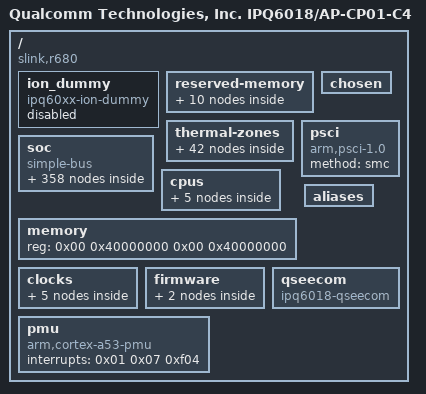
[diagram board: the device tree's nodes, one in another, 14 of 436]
/dts-v1/;

/ {
	qcom,board-id = <0x08 0x00>;
	qcom,pmic-id = <0x00 0x00 0x00 0x00>;
	rpm_version = [43 52 4d 2d 52 50 4d 2e 42 46 2e 32 2e 34 2e 31 2d 30 30 30 39 35 0a];
	tz_version = [43 52 4d 2d 54 5a 2e 57 4e 53 2e 35 2e 31 2d 30 30 31 33 32 0a];
	soc_version_major = <0x1000000>;
	machid = <0x3000308>;
	#size-cells = <0x02>;
	cpu_type = <0xa5010000>;
	interrupt-parent = <0x01>;
	compatible = "slink,r680\0qcom,ipq6018";
	#address-cells = <0x02>;
	model = "Qualcomm Technologies, Inc. IPQ6018/AP-CP01-C4";
	flash_type = <0x5000000>;
	qcom,msm-id = <0x192 0x00 0x193 0x00>;
	soc_version_minor = <0x00>;
	boot_version = [63 72 6d 2d 75 62 75 6e 74 75 31 32 34 2d 42 4f 4f 54 2e 58 46 2e 30 2e 33 2d 30 30 31 30 30 2d 49 50 51 36 30 78 78 4c 5a 42 2d 31 0a];

	ion_dummy {
		compatible = "ipq60xx-ion-dummy";
		status = "disabled";
	};

	reserved-memory {
		ranges;
		#size-cells = <0x02>;
		#address-cells = <0x02>;

		nss@40000000 {
			reg = <0x00 0x40000000 0x00 0x1000000>;
			no-map;
		};

		sbl@4A500000 {
			reg = <0x00 0x4a500000 0x00 0x100000>;
			no-map;
		};

		tzapp@49B00000 {
			reg = <0x00 0x49b00000 0x00 0x600000>;
			no-map;
		};

		rpm_msg_ram@0x60000 {
			linux,phandle = <0x13>;
			reg = <0x00 0x60000 0x00 0x6000>;
			phandle = <0x13>;
			no-map;
		};

		m3_dump@50100000 {
			reg = <0x00 0x50100000 0x00 0x100000>;
			no-map;
		};

		q6_etr_dump@1 {
			linux,phandle = <0x18>;
			reg = <0x00 0x50000000 0x00 0x100000>;
			phandle = <0x18>;
			no-map;
		};

		wcnss@4ab00000 {
			linux,phandle = <0x17>;
			reg = <0x00 0x4ab00000 0x00 0x5500000>;
			phandle = <0x17>;
			no-map;
		};

		tz@4A600000 {
			reg = <0x00 0x4a600000 0x00 0x400000>;
			no-map;
		};

		smem@4AA00000 {
			linux,phandle = <0x11>;
			reg = <0x00 0x4aa00000 0x00 0x100000>;
			phandle = <0x11>;
			no-map;
		};

		uboot@4A100000 {
			reg = <0x00 0x4a100000 0x00 0x400000>;
			no-map;
		};
	};

	thermal-zones {

		tsens_tz_sensor7 {
			thermal-sensors = <0x53 0x07>;
			polling-delay = <0x00>;
			polling-delay-passive = <0x00>;

			trips {

				cpu-critical-hi {
					temperature = <0x7d>;
					type = "critical_high";
					hysteresis = <0x02>;
				};

				cpu-config-hi {
					temperature = <0x69>;
					type = "configurable_hi";
					hysteresis = <0x02>;
				};

				cpu-critical-low {
					temperature = <0x00>;
					type = "critical_low";
					hysteresis = <0x02>;
				};

				cpu-config-lo {
					temperature = <0x5f>;
					type = "configurable_lo";
					hysteresis = <0x02>;
				};
			};
		};

		tsens_tz_sensor15 {
			thermal-sensors = <0x53 0x0f>;
			polling-delay = <0x00>;
			polling-delay-passive = <0x00>;

			trips {

				cpu-critical-hi {
					temperature = <0x7d>;
					type = "critical_high";
					hysteresis = <0x02>;
				};

				cpu-config-hi {
					temperature = <0x69>;
					type = "configurable_hi";
					hysteresis = <0x02>;
				};

				cpu-critical-low {
					temperature = <0x00>;
					type = "critical_low";
					hysteresis = <0x02>;
				};

				cpu-config-lo {
					temperature = <0x5f>;
					type = "configurable_lo";
					hysteresis = <0x02>;
				};
			};
		};

		tsens_tz_sensor13 {
			thermal-sensors = <0x53 0x0d>;
			polling-delay = <0x00>;
			polling-delay-passive = <0x00>;

			trips {

				cpu-critical-hi {
					temperature = <0x7d>;
					type = "critical_high";
					hysteresis = <0x02>;
				};

				cpu-config-hi {
					temperature = <0x69>;
					type = "configurable_hi";
					hysteresis = <0x02>;
				};

				cpu-critical-low {
					temperature = <0x00>;
					type = "critical_low";
					hysteresis = <0x02>;
				};

				cpu-config-lo {
					temperature = <0x5f>;
					type = "configurable_lo";
					hysteresis = <0x02>;
				};
			};
		};

		tsens_tz_sensor8 {
			thermal-sensors = <0x53 0x08>;
			polling-delay = <0x00>;
			polling-delay-passive = <0x00>;

			trips {

				cpu-critical-hi {
					temperature = <0x7d>;
					type = "critical_high";
					hysteresis = <0x02>;
				};

				cpu-config-hi {
					temperature = <0x69>;
					type = "configurable_hi";
					hysteresis = <0x02>;
				};

				cpu-critical-low {
					temperature = <0x00>;
					type = "critical_low";
					hysteresis = <0x02>;
				};

				cpu-config-lo {
					temperature = <0x5f>;
					type = "configurable_lo";
					hysteresis = <0x02>;
				};
			};
		};

		tsens_tz_sensor4 {
			thermal-sensors = <0x53 0x04>;
			polling-delay = <0x00>;
			polling-delay-passive = <0x00>;

			trips {

				cpu-critical-hi {
					temperature = <0x7d>;
					type = "critical_high";
					hysteresis = <0x02>;
				};

				cpu-config-hi {
					temperature = <0x69>;
					type = "configurable_hi";
					hysteresis = <0x02>;
				};

				cpu-critical-low {
					temperature = <0x00>;
					type = "critical_low";
					hysteresis = <0x02>;
				};

				cpu-config-lo {
					temperature = <0x5f>;
					type = "configurable_lo";
					hysteresis = <0x02>;
				};
			};
		};

		tsens_tz_sensor14 {
			thermal-sensors = <0x53 0x0e>;
			polling-delay = <0x00>;
			polling-delay-passive = <0x00>;

			trips {

				cpu-critical-hi {
					temperature = <0x7d>;
					type = "critical_high";
					hysteresis = <0x02>;
				};

				cpu-config-hi {
					temperature = <0x69>;
					type = "configurable_hi";
					hysteresis = <0x02>;
				};

				cpu-critical-low {
					temperature = <0x00>;
					type = "critical_low";
					hysteresis = <0x02>;
				};

				cpu-config-lo {
					temperature = <0x5f>;
					type = "configurable_lo";
					hysteresis = <0x02>;
				};
			};
		};

		tsens_tz_sensor5 {
			thermal-sensors = <0x53 0x05>;
			polling-delay = <0x00>;
			polling-delay-passive = <0x00>;

			trips {

				cpu-critical-hi {
					temperature = <0x7d>;
					type = "critical_high";
					hysteresis = <0x02>;
				};

				cpu-config-hi {
					temperature = <0x69>;
					type = "configurable_hi";
					hysteresis = <0x02>;
				};

				cpu-critical-low {
					temperature = <0x00>;
					type = "critical_low";
					hysteresis = <0x02>;
				};

				cpu-config-lo {
					temperature = <0x5f>;
					type = "configurable_lo";
					hysteresis = <0x02>;
				};
			};
		};
	};

	chosen {
		bootargs = "console=ttyMSM0,115200n8 root=PARTUUID=3625f940-31af-fa1a-fc93-c758963eba40 gpt rootwait";
		bootargs-append = " swiotlb=1 coherent_pool=2M";
	};

	soc {
		ranges = <0x00 0x00 0x00 0xffffffff>;
		#size-cells = <0x01>;
		compatible = "simple-bus";
		#address-cells = <0x01>;

		funnel@6120000 {
			arm,primecell-periphid = <0x3b908>;
			reg = <0x6120000 0x1000>;
			clocks = <0x03 0xbf 0x03 0xbe>;
			compatible = "arm,primecell";
			coresight-name = "coresight-funnel-right";
			reg-names = "funnel-base";
			clock-names = "apb_pclk\0core_a_clk";

			ports {
				#size-cells = <0x00>;
				#address-cells = <0x01>;

				port@0 {
					reg = <0x00>;

					endpoint {
						linux,phandle = <0x2e>;
						phandle = <0x2e>;
						remote-endpoint = <0x36>;
					};
				};

				port@1 {
					reg = <0x03>;

					endpoint {
						linux,phandle = <0x38>;
						slave-mode;
						phandle = <0x38>;
						remote-endpoint = <0x37>;
					};
				};
			};
		};

		funnel@6100000 {
			arm,primecell-periphid = <0x3b908>;
			reg = <0x6100000 0x1000>;
			clocks = <0x03 0xbf 0x03 0xbe>;
			compatible = "arm,primecell";
			coresight-name = "coresight-funnel-center";
			reg-names = "funnel-base";
			clock-names = "apb_pclk\0core_a_clk";

			ports {
				#size-cells = <0x00>;
				#address-cells = <0x01>;

				port@0 {
					reg = <0x00>;

					endpoint {
						linux,phandle = <0x2d>;
						phandle = <0x2d>;
						remote-endpoint = <0x33>;
					};
				};

				port@1 {
					reg = <0x02>;

					endpoint {
						linux,phandle = <0x47>;
						slave-mode;
						phandle = <0x47>;
						remote-endpoint = <0x34>;
					};
				};
			};
		};

		cti@601b000 {
			reg = <0x601b000 0x1000>;
			clocks = <0x03 0xbf 0x03 0xbe>;
			compatible = "arm,coresight-cti";
			coresight-name = "coresight-cti11";
			reg-names = "cti-base";
			clock-names = "core_clk\0core_a_clk";
		};

		cti@6198000 {
			cpu = <0x3d>;
			reg = <0x6198000 0x1000>;
			clocks = <0x03 0xbf 0x03 0xbe>;
			compatible = "arm,coresight-cti";
			coresight-name = "coresight-cti-cpu0";
			reg-names = "cti-base";
			clock-names = "core_clk\0core_a_clk";
		};

		qrng@e1000 {
			reg = <0xe3000 0x1000>;
			clocks = <0x03 0x88>;
			compatible = "qcom,prng-ipq807x";
			clock-names = "core";
			status = "ok";
		};

		nss@40000000 {
			qcom,ipv4-enabled;
			qcom,crypto-enabled;
			qcom,load-addr = <0x40000000>;
			qcom,num-irq = <0x0a>;
			qcom,ppe-enabled;
			qcom,tun6rd-enabled;
			qcom,mirror-enabled;
			qcom,gre-enabled;
			qcom,vxlan-enabled;
			qcom,tunipip6-enabled;
			qcom,qvpn-enabled;
			qcom,gre-redir-enabled;
			qcom,tls-enabled;
			qcom,wlanredirect-enabled;
			qcom,match-enabled;
			qcom,ipsec-enabled;
			reg = <0x39000000 0x1000 0xb111000 0x1000>;
			qcom,l2tpv2-enabled;
			qcom,pptp-enabled;
			qcom,gre-redir-mark-enabled;
			qcom,map-t-enabled;
			clocks = <0x03 0x64 0x03 0x72 0x03 0x61 0x03 0x5f 0x03 0x78 0x03 0xae 0x03 0x79 0x03 0xf4 0x03 0x5e 0x03 0x5d 0x03 0x74 0x03 0x73 0x03 0x7a 0x03 0x82 0x03 0x80 0x03 0x81 0x03 0xaf 0x03 0xf0 0x03 0xf2>;
			qcom,bridge-enabled;
			compatible = "qcom,nss";
			qcom,mid-frequency = <0x2ca1c800>;
			qcom,portid-enabled;
			qcom,wlan-dataplane-offload-enabled;
			qcom,low-frequency = "\v(r";
			qcom,vlan-enabled;
			qcom,pvxlan-enabled;
			qcom,num-queue = <0x04>;
			qcom,shaping-enabled;
			qcom,ipv4-reasm-enabled;
			qcom,ipv6-enabled;
			qcom,num-pri = <0x04>;
			qcom,id = <0x00>;
			interrupts = <0x00 0x192 0x01 0x00 0x191 0x01 0x00 0x190 0x01 0x00 0x18f 0x01 0x00 0x18e 0x01 0x00 0x18d 0x01 0x00 0x18c 0x01 0x00 0x18b 0x01 0x00 0x18a 0x01 0x00 0x189 0x01>;
			qcom,dtls-enabled;
			qcom,pppoe-enabled;
			qcom,ipv6-reasm-enabled;
			reg-names = "nphys\0qgic-phys";
			qcom,max-frequency = <0x59439000>;
			qcom,clmap-enabled;
			clock-names = "nss-noc-clk\0nss-ptp-ref-clk\0nss-csr-clk\0nss-cfg-clk\0nss-nssnoc-qosgen-ref-clk\0nss-nssnoc-snoc-clk\0nss-nssnoc-timeout-ref-clk\0nss-mem-noc-ubi32-clk\0nss-ce-axi-clk\0nss-ce-apb-clk\0nss-nssnoc-ce-axi-clk\0nss-nssnoc-ce-apb-clk\0nss-nssnoc-ahb-clk\0nss-core-clk\0nss-ahb-clk\0nss-axi-clk\0nss-nc-axi-clk\0nss-utcm-clk\0nss-snoc-nssnoc-clk";
			qcom,capwap-enabled;
		};

		extcon_usb {
			compatible = "linux,extcon-usb-gpio";
			status = "disabled";
		};

		qcom_mdss_qpic_panel {
			qcom,mdss-pan-res = <0x320 0x1e0>;
			compatible = "qcom,mdss-qpic-panel";
			label = "qpic lcd panel";
			qcom,mdss-pan-bpp = <0x12>;
			qcom,refresh_rate = <0x3c>;
			status = "disabled";
		};

		qusb@79000 {
			linux,phandle = <0x08>;
			phy_type = "utmi";
			reg = <0x79000 0x180 0x8af8800 0x400 0x1841030 0x04 0x8a0c12c 0x04>;
			phandle = <0x08>;
			reset-names = "usb2_phy_reset";
			compatible = "qcom,qusb2phy";
			qcom,qusb-phy-init-seq = <0x14 0x00 0xf8 0x80 0xb3 0x84 0x83 0x88 0xc0 0x8c 0x30 0x08 0x79 0x0c 0x21 0x10 0x00 0x90 0x00 0x18 0x14 0x9c 0x80 0x04 0x9f 0x1c>;
			reg-names = "qusb_phy_base\0qscratch_base\0ref_clk_addr\0usb3_guctl_addr";
			resets = <0x03 0x2b>;
			status = "ok";
		};

		cti@601d000 {
			reg = <0x601d000 0x1000>;
			clocks = <0x03 0xbf 0x03 0xbe>;
			compatible = "arm,coresight-cti";
			coresight-name = "coresight-cti13";
			reg-names = "cti-base";
			clock-names = "core_clk\0core_a_clk";
		};

		cti@6018000 {
			linux,phandle = <0x26>;
			reg = <0x6018000 0x1000>;
			phandle = <0x26>;
			clocks = <0x03 0xbf 0x03 0xbe>;
			compatible = "arm,coresight-cti";
			coresight-name = "coresight-cti8";
			reg-names = "cti-base";
			clock-names = "core_clk\0core_a_clk";
		};

		gpio_keys {
			pinctrl-0 = <0x4b>;
			pinctrl-names = "default";
			compatible = "gpio-keys";

			reset {
				gpios = <0x0c 0x13 0x01>;
				debounce-interval = <0x3c>;
				linux,code = <0x198>;
				label = "reset";
				linux,input-type = <0x01>;
			};
		};

		tmc@6047000 {
			arm,primecell-periphid = <0x3b961>;
			reg = <0x6047000 0x1000>;
			clocks = <0x03 0xbf 0x03 0xbe>;
			coresight-ctis = <0x25 0x26>;
			compatible = "arm,primecell";
			arm,default-sink;
			coresight-name = "coresight-tmc-etf";
			reg-names = "tmc-base";
			clock-names = "apb_pclk\0core_a_clk";

			ports {
				#size-cells = <0x00>;
				#address-cells = <0x01>;

				port@0 {
					reg = <0x00>;

					endpoint {
						linux,phandle = <0x29>;
						phandle = <0x29>;
						remote-endpoint = <0x2a>;
					};
				};

				port@1 {
					reg = <0x00>;

					endpoint {
						linux,phandle = <0x2c>;
						slave-mode;
						phandle = <0x2c>;
						remote-endpoint = <0x2b>;
					};
				};
			};
		};

		dma@704000 {
			linux,phandle = <0x05>;
			reg = <0x704000 0x20000>;
			phandle = <0x05>;
			clocks = <0x03 0x56>;
			compatible = "qcom,bam-v1.7.0";
			#dma-cells = <0x01>;
			qcom,ee = <0x01>;
			interrupts = <0x00 0xcf 0x00>;
			qcom,config-pipe-trust-reg = <0x00>;
			clock-names = "bam_clk";
			qcom,controlled-remotely = <0x01>;
		};

		stm@6002000 {
			arm,primecell-periphid = <0x3b962>;
			reg = <0x6002000 0x1000 0x9280000 0x180000>;
			clocks = <0x03 0xbf 0x03 0xbe>;
			compatible = "arm,primecell";
			coresight-name = "coresight-stm";
			reg-names = "stm-base\0stm-data-base";
			clock-names = "apb_pclk\0core_a_clk";

			port {

				endpoint {
					linux,phandle = <0x31>;
					phandle = <0x31>;
					remote-endpoint = <0x46>;
				};
			};
		};

		cti@6016000 {
			reg = <0x6016000 0x1000>;
			clocks = <0x03 0xbf 0x03 0xbe>;
			compatible = "arm,coresight-cti";
			coresight-name = "coresight-cti6";
			reg-names = "cti-base";
			clock-names = "core_clk\0core_a_clk";
		};

		qcom,glink-ssr-rpm {
			linux,phandle = <0x1d>;
			qcom,xprt = "smem";
			qcom,edge = "rpm";
			qcom,no-notify-edges;
			phandle = <0x1d>;
			compatible = "qcom,glink_ssr";
			label = "rpm";
		};

		cti@601f000 {
			reg = <0x601f000 0x1000>;
			clocks = <0x03 0xbf 0x03 0xbe>;
			compatible = "arm,coresight-cti";
			coresight-name = "coresight-cti15";
			reg-names = "cti-base";
			clock-names = "core_clk\0core_a_clk";
		};

		leds {
			pinctrl-0 = <0x4c>;
			pinctrl-names = "default";
			compatible = "gpio-leds";

			led@34 {
				gpios = <0x0c 0x22 0x00>;
				default-state = "off";
				label = "led_system";
				linux,default-trigger = "timer";
			};

			led@18 {
				gpios = <0x0c 0x12 0x00>;
				default-state = "off";
				label = "led_rssi1";
				linux,default-trigger = "rssi1";
			};

			led@24 {
				gpios = <0x0c 0x18 0x00>;
				default-state = "off";
				label = "led_rssi4";
				linux,default-trigger = "rssi4";
			};

			led@22 {
				gpios = <0x0c 0x16 0x00>;
				default-state = "off";
				label = "led_rssi2";
				linux,default-trigger = "rssi2";
			};

			led@26 {
				gpios = <0x0c 0x1a 0x00>;
				default-state = "off";
				label = "sfp_disable";
				linux,default-trigger = "sfp_disable";
			};

			led@35 {
				gpios = <0x0c 0x23 0x00>;
				default-state = "off";
				label = "led_5g";
				linux,default-trigger = "led_5g";
			};

			led@37 {
				gpios = <0x0c 0x25 0x00>;
				default-state = "off";
				label = "led_2g";
				linux,default-trigger = "led_2g";
			};

			led@23 {
				gpios = <0x0c 0x17 0x00>;
				default-state = "off";
				label = "led_rssi3";
				linux,default-trigger = "rssi3";
			};
		};

		mailbox@b111000 {
			linux,phandle = <0x22>;
			qcom,ipc = <0x10 0x08 0x08>;
			phandle = <0x22>;
			compatible = "qcom,msm8996-apcs-hmss-global";
			#mbox-cells = <0x01>;
		};

		edma@3ab00000 {
			qcom,rxfill-ring-start = <0x07>;
			qcom,rxdesc-ring-start = <0x0f>;
			reg = <0x3ab00000 0xabe00>;
			reset-names = "edma_rst";
			compatible = "qcom,edma";
			qcom,txcmpl-ring-start = <0x17>;
			qcom,txdesc-ring-start = <0x17>;
			qcom,txcmpl-rings = <0x01>;
			qcom,txdesc-rings = <0x01>;
			interrupts = <0x00 0x17a 0x04 0x00 0x162 0x04 0x00 0x15a 0x04 0x00 0x17b 0x04>;
			qcom,rxfill-rings = <0x01>;
			reg-names = "edma-reg-base";
			resets = <0x03 0x6d>;
			qcom,rxdesc-rings = <0x01>;
		};

		qcom,msm-adsprpc-mem {
			compatible = "qcom,msm-adsprpc-mem-region";
			status = "disabled";
		};

		replicator@6046000 {
			arm,primecell-periphid = <0x3b909>;
			reg = <0x6046000 0x1000>;
			clocks = <0x03 0xbf 0x03 0xbe>;
			compatible = "arm,primecell";
			coresight-name = "coresight-replicator";
			reg-names = "replicator-base";
			clock-names = "apb_pclk\0core_a_clk";

			ports {
				#size-cells = <0x00>;
				#address-cells = <0x01>;

				port@0 {
					reg = <0x00>;

					endpoint {
						linux,phandle = <0x27>;
						phandle = <0x27>;
						remote-endpoint = <0x28>;
					};
				};

				port@1 {
					reg = <0x00>;

					endpoint {
						linux,phandle = <0x2a>;
						slave-mode;
						phandle = <0x2a>;
						remote-endpoint = <0x29>;
					};
				};
			};
		};

		gcc@1800000 {
			#reset-cells = <0x01>;
			linux,phandle = <0x03>;
			reg = <0x1800000 0x80000>;
			#clock-cells = <0x01>;
			phandle = <0x03>;
			compatible = "qcom,gcc-ipq6018";
		};

		sdcc1ice@7808000 {
			qcom,instance-type = "sdcc";
			linux,phandle = <0x1e>;
			qcom,msm-bus,vectors-KBps = <0x4e 0x200 0x00 0x00 0x4e 0x200 0x3e8 0x00>;
			reg = <0x7808000 0x2000>;
			phandle = <0x1e>;
			compatible = "qcom,ice";
			qcom,bus-vector-names = "MIN\0MAX";
			interrupts = <0x00 0x138 0x00>;
		};

		serial@78b1000 {
			pinctrl-0 = <0x04>;
			reg = <0x78b1000 0x200>;
			pinctrl-names = "default";
			clocks = <0x03 0x52 0x03 0x43>;
			compatible = "qcom,msm-uartdm-v1.4\0qcom,msm-uartdm";
			interrupts = <0x00 0x132 0x04>;
			clock-names = "core\0iface";
			status = "ok";
		};

		q6v5_wcss@CD00000 {
			qcom,smem-state-names = "shutdown\0stop";
			linux,phandle = <0x1a>;
			memory-region = <0x17 0x18>;
			qca,sec-reset-cmd = <0x18>;
			reg = <0xcd00000 0x4040 0x194f000 0x10 0x1952000 0x10 0x4ab000 0x20 0x1818000 0x110 0x1859000 0x10 0x1945000 0x10>;
			phandle = <0x1a>;
			clocks = <0x03 0xce 0x03 0xcf 0x03 0xd0 0x03 0xd1 0x03 0xcb 0x03 0xcc 0x03 0xcd 0x03 0xd2 0x03 0xd4>;
			interrupt-names = "wdog\0qcom,gpio-err-fatal\0qcom,gpio-err-ready\0qcom,gpio-stop-ack";
			compatible = "qca,q6v5-wcss-rproc-ipq60xx";
			qca,secure;
			firmware = "IPQ6018/q6_fw.mdt";
			interrupts-extended = <0x01 0x00 0x145 0x01 0x15 0x00 0x00 0x15 0x01 0x00 0x15 0x03 0x00>;
			qcom,smem-states = <0x16 0x00 0x16 0x01>;
			reg-names = "wcss-base\0tcsr-q6-base\0tcsr-base\0mpm-base\0gcc-wcss-bcr-base\0gcc-wcss-misc-base\0tcsr-global";
			qca,extended-intc;
			qca,auto-restart;
			clock-names = "wcss_axi_m_clk\0sys_noc_wcss_ahb_clk\0q6_axim_clk\0q6ss_atbm_clk\0q6ss_pclkdbg_clk\0q6_tsctr_1to2_clk\0wcss_core_tbu_clk\0wcss_q6_tbu_clk\0gcc_q6_ahb_clk";
		};

		crypto@73a000 {
			dma-names = "rx\0tx";
			dmas = <0x05 0x02 0x05 0x03>;
			reg = <0x73a000 0x6000>;
			clocks = <0x03 0x56 0x03 0x57 0x03 0x58>;
			compatible = "qcom,crypto-v5.1";
			clock-names = "iface\0bus\0core";
		};

		slim@a2c0000 {
			reg = <0xa2c0000 0x2c000 0xa284000 0x2a000>;
			interrupt-names = "slimbus_irq\0slimbus_bam_irq";
			compatible = "qcom,slim-ngd";
			cell-index = <0x01>;
			qcom,apps-ch-pipes = <0x7c0000>;
			interrupts = <0x00 0x1f 0x00 0x00 0x20 0x00>;
			reg-names = "slimbus_physical\0slimbus_bam_physical";
			qcom,ea-pc = <0x320>;
			status = "disabled";
		};

		clock-controller@b1b8000 {
			linux,phandle = <0x52>;
			reg = <0xb1b8000 0x1000>;
			phandle = <0x52>;
			compatible = "qcom,arm-cortex-acc";
		};

		funnel@6041000 {
			arm,primecell-periphid = <0x3b908>;
			reg = <0x6041000 0x1000>;
			clocks = <0x03 0xbf 0x03 0xbe>;
			compatible = "arm,primecell";
			coresight-name = "coresight-funnel-in0";
			reg-names = "funnel-base";
			clock-names = "apb_pclk\0core_a_clk";

			ports {
				#size-cells = <0x00>;
				#address-cells = <0x01>;

				port@2 {
					reg = <0x04>;

					endpoint {
						linux,phandle = <0x36>;
						slave-mode;
						phandle = <0x36>;
						remote-endpoint = <0x2e>;
					};
				};

				port@0 {
					reg = <0x00>;

					endpoint {
						linux,phandle = <0x2b>;
						phandle = <0x2b>;
						remote-endpoint = <0x2c>;
					};
				};

				port@1 {
					reg = <0x03>;

					endpoint {
						linux,phandle = <0x33>;
						slave-mode;
						phandle = <0x33>;
						remote-endpoint = <0x2d>;
					};
				};

				port@6 {
					reg = <0x00>;

					endpoint {
						linux,phandle = <0x45>;
						slave-mode;
						phandle = <0x45>;
						remote-endpoint = <0x32>;
					};
				};

				port@4 {
					reg = <0x06>;

					endpoint {
						linux,phandle = <0x48>;
						slave-mode;
						phandle = <0x48>;
						remote-endpoint = <0x30>;
					};
				};

				port@3 {
					reg = <0x05>;

					endpoint {
						linux,phandle = <0x35>;
						slave-mode;
						phandle = <0x35>;
						remote-endpoint = <0x2f>;
					};
				};

				port@5 {
					reg = <0x07>;

					endpoint {
						linux,phandle = <0x46>;
						slave-mode;
						phandle = <0x46>;
						remote-endpoint = <0x31>;
					};
				};
			};
		};

		qcom,glink-ssr-adsp {
			qcom,xprt = "smem";
			qcom,edge = "adsp";
			qcom,notify-edges = <0x1d>;
			compatible = "qcom,glink_ssr";
			label = "q6v6-adsp";
			status = "disabled";
		};

		qcom,ipc_router_adsp_xprt {
			qcom,xprt-linkid = <0x01>;
			qcom,ch-name = "IPCRTR";
			qcom,glink-xprt = "smem";
			compatible = "qcom,ipc_router_glink_xprt";
			qcom,fragmented-data;
			qcom,xprt-remote = "adsp";
			qcom,xprt-version = <0x01>;
			status = "disabled";
		};

		qpic-nand@79b0000 {
			dma-names = "tx\0rx\0cmd";
			param-read-addr-cycle = <0x01>;
			#size-cells = <0x00>;
			dmas = <0x06 0x00 0x06 0x01 0x06 0x02>;
			reg = <0x79b0000 0x10000>;
			clocks = <0x03 0x8a 0x03 0x89>;
			compatible = "qcom,ebi2-nandc-bam-v1.5.0";
			#address-cells = <0x01>;
			clock-names = "core\0aon";
			status = "disabled";

			nandcs@0 {
				nand-ecc-step-size = <0x200>;
				#size-cells = <0x01>;
				reg = <0x00>;
				nand-bus-width = <0x08>;
				compatible = "qcom,nandcs";
				#address-cells = <0x01>;
				nand-ecc-strength = <0x04>;
			};
		};

		qcom,diag@0 {
			compatible = "qcom,diag";
			status = "ok";
		};

		ess-uniphy@7a00000 {
			uniphy_access_mode = "local bus";
			reg = <0x7a00000 0x30000>;
			compatible = "qcom,ess-uniphy";
		};

		qcom,test@0 {
			compatible = "qcom,testmhi";
			status = "disabled";
		};

		q6v5_m3 {
			linux,phandle = <0x19>;
			phandle = <0x19>;
			compatible = "qca,q6v5-m3-rproc";
			qcom,restart-group = <0x19 0x1a>;
			firmware = "IPQ6018/m3_fw.mdt";
			qca,auto-restart;
		};

		qcom,msm-imem@8600000 {
			ranges = <0x00 0x8600000 0x1000>;
			#size-cells = <0x01>;
			reg = <0x8600000 0x1000>;
			compatible = "qcom,msm-imem";
			#address-cells = <0x01>;

			mem_dump_table@10 {
				reg = <0x10 0x08>;
				compatible = "qcom,msm-imem-mem_dump_table";
			};
		};

		etm@619f000 {
			arm,primecell-periphid = <0x3b95d>;
			cpu = <0x43>;
			reg = <0x619f000 0x1000>;
			clocks = <0x03 0xbf 0x03 0xbe>;
			compatible = "arm,primecell";
			coresight-name = "coresight-etm3";
			clock-names = "apb_pclk\0core_a_clk";

			port {

				endpoint {
					linux,phandle = <0x3c>;
					phandle = <0x3c>;
					remote-endpoint = <0x44>;
				};
			};
		};

		wifi@c000000 {
			qcom,rproc = <0x24>;
			qcom,tgt-mem-mode = <0x00>;
			qcom,pta-priority = <0x80800505>;
			qcom,pta-num = <0x00>;
			qcom,hw-mode-id = <0x01>;
			reg = <0xc000000 0x1000000>;
			qcom,caldb-addr = <0x4b500000 0x4b500000 0x4b500000 0x00 0x00>;
			qcom,coex-mode = <0x02>;
			interrupt-names = "misc-pulse1\0misc-latch\0sw-exception\0ce0\0ce1\0ce2\0ce3\0ce4\0ce5\0ce6\0ce7\0ce8\0ce9\0ce10\0ce11\0host2wbm-desc-feed\0host2reo-re-injection\0host2reo-command\0host2rxdma-monitor-ring3\0host2rxdma-monitor-ring2\0host2rxdma-monitor-ring1\0reo2ost-exception\0wbm2host-rx-release\0reo2host-status\0reo2host-destination-ring4\0reo2host-destination-ring3\0reo2host-destination-ring2\0reo2host-destination-ring1\0rxdma2host-monitor-destination-mac3\0rxdma2host-monitor-destination-mac2\0rxdma2host-monitor-destination-mac1\0ppdu-end-interrupts-mac3\0ppdu-end-interrupts-mac2\0ppdu-end-interrupts-mac1\0rxdma2host-monitor-status-ring-mac3\0rxdma2host-monitor-status-ring-mac2\0rxdma2host-monitor-status-ring-mac1\0host2rxdma-host-buf-ring-mac3\0host2rxdma-host-buf-ring-mac2\0host2rxdma-host-buf-ring-mac1\0rxdma2host-destination-ring-mac3\0rxdma2host-destination-ring-mac2\0rxdma2host-destination-ring-mac1\0host2tcl-input-ring4\0host2tcl-input-ring3\0host2tcl-input-ring2\0host2tcl-input-ring1\0wbm2host-tx-completions-ring3\0wbm2host-tx-completions-ring2\0wbm2host-tx-completions-ring1\0tcl2host-status-ring";
			compatible = "qcom,cnss-qca6018\0qcom,ipq6018-wifi";
			qcom,coex-algo = <0x02>;
			qcom,bt-priority-time = <0x12>;
			qcom,bt-active-time = <0x18>;
			qcom,caldb-size = <0x480000>;
			interrupts = <0x00 0x140 0x01 0x00 0x13f 0x01 0x00 0x13e 0x01 0x00 0x13c 0x01 0x00 0x13b 0x01 0x00 0x13a 0x01 0x00 0x137 0x01 0x00 0x136 0x01 0x00 0x19b 0x01 0x00 0x19a 0x01 0x00 0x28 0x01 0x00 0x27 0x01 0x00 0x12e 0x01 0x00 0x12d 0x01 0x00 0x25 0x01 0x00 0x24 0x01 0x00 0x128 0x01 0x00 0x127 0x01 0x00 0x126 0x01 0x00 0x125 0x01 0x00 0x124 0x01 0x00 0x123 0x01 0x00 0x122 0x01 0x00 0x121 0x01 0x00 0x120 0x01 0x00 0xef 0x01 0x00 0xec 0x01 0x00 0xeb 0x01 0x00 0xea 0x01 0x00 0xe9 0x01 0x00 0xe8 0x01 0x00 0xe7 0x01 0x00 0xe6 0x01 0x00 0xe5 0x01 0x00 0xe4 0x01 0x00 0xe0 0x01 0x00 0xdf 0x01 0x00 0xcb 0x01 0x00 0xb7 0x01 0x00 0xb4 0x01 0x00 0xb3 0x01 0x00 0xb2 0x01 0x00 0xb1 0x01 0x00 0xb0 0x01 0x00 0xa3 0x01 0x00 0xa2 0x01 0x00 0xa0 0x01 0x00 0x9f 0x01 0x00 0x9e 0x01 0x00 0x9d 0x01 0x00 0x9c 0x01>;
			qcom,bdf-addr = <0x4abc0000 0x4abc0000 0x4abc0000 0x00 0x00>;
			status = "ok";
		};

		qcom,nss_crypto {
			qcom,max-contexts = <0x40>;
			ranges;
			#size-cells = <0x01>;
			compatible = "qcom,nss-crypto";
			#address-cells = <0x01>;
			qcom,max-context-size = <0x20>;
			status = "ok";

			eip197_node {
				qcom,sha256-hmac;
				qcom,md5-hash;
				qcom,aes128-cbc-sha384-hmac;
				qcom,aes192-cbc-sha160-hmac;
				qcom,aes128-cbc;
				qcom,3des-cbc;
				qcom,aes192-ctr;
				qcom,aes128-ctr-sha160-hmac;
				qcom,aes128-ctr-sha512-hmac;
				qcom,aes256-ctr-sha160-hmac;
				qcom,sha160-hash;
				qcom,aes192-cbc;
				qcom,aes256-ctr;
				qcom,sha512-hmac;
				qcom,aes192-ctr-sha160-hmac;
				qcom,sha256-hash;
				qcom,transform-enabled;
				qcom,aes256-cbc;
				qcom,aes192-cbc-sha384-hmac;
				qcom,aes256-ecb;
				qcom,aes192-cbc-sha512-hmac;
				reg = <0x39800000 0x7ffff>;
				qcom,sha224-hmac;
				qcom,dma-mask = <0xff>;
				qcom,aes128-cbc-sha256-hmac;
				qcom,3des-cbc-md5-hmac;
				qcom,aes192-ctr-md5-hmac;
				clocks = <0x03 0x60 0x03 0x75 0x03 0x5c>;
				qcom,aes128-ctr-sha256-hmac;
				qcom,sha384-hash;
				qcom,aes192-ecb;
				qcom,aes256-gcm-gmac;
				compatible = "qcom,eip197";
				qcom,aes256-ctr-md5-hmac;
				qcom,aes192-ctr-sha256-hmac;
				qcom,md5-hmac;
				qcom,sha224-hash;
				qcom,aes192-cbc-sha256-hmac;
				qcom,aes128-cbc-md5-hmac;
				qcom,aes128-cbc-sha160-hmac;
				qcom,aes256-cbc-sha160-hmac;
				qcom,sha160-hmac;
				qcom,aes128-gcm-gmac;
				qcom,aes256-cbc-sha384-hmac;
				clock-frequency = <0x00 0x11e1a300 0x00 0x11e1a300 0x00 0x11e1a300>;
				qcom,aes192-gcm-gmac;
				qcom,aes128-ctr-sha384-hmac;
				qcom,aes256-ctr-sha256-hmac;
				qcom,aes256-cbc-md5-hmac;
				qcom,aes192-ctr-sha512-hmac;
				qcom,3des-cbc-sha256-hmac;
				qcom,aes192-ctr-sha384-hmac;
				qcom,3des-cbc-sha160-hmac;
				qcom,aes256-cbc-sha512-hmac;
				qcom,aes256-cbc-sha256-hmac;
				qcom,aes128-ctr-md5-hmac;
				qcom,aes128-ctr;
				qcom,aes128-cbc-sha512-hmac;
				qcom,sha512-hash;
				qcom,sha384-hmac;
				reg-names = "crypto_pbase";
				qcom,aes256-ctr-sha384-hmac;
				qcom,aes256-ctr-sha512-hmac;
				qcom,aes192-cbc-md5-hmac;
				qcom,aes128-ecb;
				clock-names = "crypto_clk\0crypto_nocclk\0crypto_ppeclk";

				engine0 {
					qcom,ofpp-enabled;
					qcom,ifpp-enabled;
					qcom,ipue-enabled;
					reg_offset = <0x80000>;
					qcom,opue-enabled;
				};
			};
		};

		qcom,msm_fastrpc {
			qcom,fastrpc-adsp-audio-pdr;
			compatible = "qcom,msm-fastrpc-compute";
			qcom,fastrpc-legacy-remote-heap;
			qcom,fastrpc-adsp-sensors-pdr;
			qcom,rpc-latency-us = <0x263>;
			status = "disabled";

			qcom,msm_fastrpc_compute_cb2 {
				iommus = <0x02 0x1005>;
				compatible = "qcom,msm-fastrpc-compute-cb";
				label = "adsprpc-smd";
			};

			qcom,msm_fastrpc_compute_cb3 {
				iommus = <0x02 0x1006>;
				compatible = "qcom,msm-fastrpc-compute-cb";
				label = "adsprpc-smd";
			};

			qcom,msm_fastrpc_compute_cb6 {
				iommus = <0x02 0x1009>;
				compatible = "qcom,msm-fastrpc-compute-cb";
				label = "adsprpc-smd";
			};

			qcom,msm_fastrpc_compute_cb8 {
				iommus = <0x02 0x100b>;
				compatible = "qcom,msm-fastrpc-compute-cb";
				label = "adsprpc-smd";
			};

			qcom,msm_fastrpc_compute_cb5 {
				iommus = <0x02 0x1008>;
				compatible = "qcom,msm-fastrpc-compute-cb";
				label = "adsprpc-smd";
			};

			qcom,msm_fastrpc_compute_cb7 {
				iommus = <0x02 0x100a>;
				compatible = "qcom,msm-fastrpc-compute-cb";
				label = "adsprpc-smd";
			};

			qcom,msm_fastrpc_compute_cb1 {
				iommus = <0x02 0x1004>;
				compatible = "qcom,msm-fastrpc-compute-cb";
				label = "adsprpc-smd";
			};

			qcom,msm_fastrpc_compute_cb4 {
				iommus = <0x02 0x1007>;
				compatible = "qcom,msm-fastrpc-compute-cb";
				label = "adsprpc-smd";
			};
		};

		qcom,glink-smem-native-xprt-adsp@4AA00000 {
			reg = <0x4aa00000 0x100000 0xb111008 0x04>;
			compatible = "qcom,glink-smem-native-xprt";
			label = "adsp";
			smem-entry = <0x1de 0x1df 0x1e0>;
			smem-entry-names = "ch\0tx_fifo\0rx_fifo";
			qcom,irq-mask = <0x800000>;
			qcom,subsys-id = <0x02>;
			interrupts = <0x00 0x18 0x01>;
			reg-names = "smem\0irq-reg-base";
			status = "disabled";
		};

		thermal-sensor@4a8000 {
			linux,phandle = <0x53>;
			reg = <0x4a8000 0x2000>;
			phandle = <0x53>;
			compatible = "qcom,ipq6018-tsens";
			tsens-up-low-int-clr-deassert-quirk;
			interrupts = <0x00 0xb8 0x00>;
			#thermal-sensor-cells = <0x01>;
			status = "ok";
		};

		qcom,rpm-glink {
			rpm-channel-name = "rpm_requests";
			qcom,glink-edge = "rpm";
			qcom,rpm-channel-type = <0x0f>;
			compatible = "qcom,rpm-glink";
			status = "disabled";
		};

		qcom_mdss_qpic@7980000 {
			dma-names = "chan";
			dmas = <0x06 0x06>;
			reg = <0x7980000 0x24000>;
			clocks = <0x03 0x8a 0x03 0x89>;
			compatible = "qcom,mdss_qpic";
			interrupts = <0x00 0x97 0x00>;
			clock-names = "core\0aon";
			status = "disabled";
		};

		qcom,usbbam@8B04000 {
			qcom,usb-bam-override-threshold = <0x4001>;
			qcom,usb-bam-fifo-baseaddr = <0x4a100000>;
			reg = <0x8b04000 0x17000>;
			qcom,bam-type = <0x00>;
			qcom,usb-bam-num-pipes = <0x04>;
			qcom,reset-bam-on-connect;
			interrupt-parent = <0x01>;
			compatible = "qcom,usb-bam-msm";
			qcom,usb-bam-max-mbps-highspeed = <0x190>;
			qcom,ignore-core-reset-ack;
			qcom,disable-clk-gating;
			qcom,usb-bam-max-mbps-superspeed = <0xe10>;
			interrupts = <0x00 0x87 0x00>;

			qcom,pipe0 {
				qcom,src-bam-pipe-index = <0x00>;
				qcom,descriptor-fifo-offset = <0xe00>;
				qcom,data-fifo-size = <0xe00>;
				qcom,pipe-num = <0x00>;
				qcom,descriptor-fifo-size = <0x200>;
				label = "ssusb-qdss-in-0";
				qcom,peer-bam-physical-address = <0x6064000>;
				qcom,usb-bam-mem-type = <0x02>;
				qcom,data-fifo-offset = <0x00>;
				qcom,dst-bam-pipe-index = <0x00>;
				qcom,peer-bam = <0x00>;
				qcom,dir = <0x01>;
			};
		};

		cti@6013000 {
			reg = <0x6013000 0x1000>;
			clocks = <0x03 0xbf 0x03 0xbe>;
			compatible = "arm,coresight-cti";
			coresight-name = "coresight-cti3";
			reg-names = "cti-base";
			clock-names = "core_clk\0core_a_clk";
		};

		qcom,rpmsg-rpm@60000 {
			mboxes = <0x14 0x08>;
			qcom,rpm-msg-ram = <0x13>;
			compatible = "qcom,glink-rpm";
			label = "rpm";
			qcom,subsys-id = <0x06>;
			interrupts = <0x00 0xa8 0x01>;
			status = "disabled";

			glink_edge {
				qcom,glink-channels = "rpm_requests";
				qcom,rpm-channel-type = <0x0f>;
			};
		};

		qcom,adsprpc_loader {
			compatible = "qti,adsprpc-loader";
			status = "disabled";
		};

		usb3@8A00000 {
			qcom,usb-dbm = <0x07>;
			ranges;
			#size-cells = <0x01>;
			reg = <0x8af8800 0x100 0x8a00000 0xcd00>;
			qca,host = <0x01>;
			clocks = <0x03 0xb9 0x03 0xba 0x03 0x9e 0x03 0xa2 0x03 0x9f 0x03 0xa0 0x03 0x9d 0x03 0xa1>;
			compatible = "qcom,ipq6018-dwc3";
			#address-cells = <0x01>;
			assigned-clocks = <0x03 0xba 0x03 0x9e 0x03 0x9f>;
			assigned-clock-rates = <0x7f27450 0x7f27450 0x16e3600>;
			reg-names = "qscratch_base\0dwc3_base";
			clock-names = "snoc_bus_timeout2\0sys_noc_axi\0master\0sleep\0mock_utmi\0cfg_ahb_clk\0aux_clk\0pipe_clk";
			status = "ok";

			dwc3@8A00000 {
				snps,nominal-elastic-buffer;
				snps,is-utmi-l1-suspend;
				snps,dis_ep_cache_eviction;
				snps,dis_u3_susphy_quirk;
				snps,hird-threshold = [00];
				usb-phy = <0x08 0x09>;
				reg = <0x8a00000 0xcd00>;
				snps,quirk-ref-clock-period = <0x29>;
				snps,usb3-u1u2-disable;
				snps,quirk-ref-clock-adjustment = <0xa87f0>;
				tx-fifo-resize;
				dr_mode = "host";
				compatible = "snps,dwc3";
				snps,dis_u2_susphy_quirk;
				interrupts = <0x00 0x8c 0x00>;
			};
		};

		qcom,glink-ssr-modem {
			qca,no-notify-edges;
			qcom,xprt = "smem";
			qcom,edge = "mpss";
			compatible = "qcom,glink_ssr";
			label = "q6v5-wcss";
		};

		qcom_q6v5_wcss@CD00000 {
			qcom,smem-state-names = "shutdown\0stop";
			linux,phandle = <0x24>;
			memory-region = <0x17 0x18>;
			reg = <0xcd00000 0x4040 0x4ab000 0x20>;
			phandle = <0x24>;
			m3_firmware = "IPQ6018/m3_fw.mdt";
			interrupt-names = "wdog\0fatal\0ready\0handover\0stop-ack";
			reset-names = "wcss_aon_reset\0wcss_reset\0wcss_q6_reset";
			compatible = "qcom,ipq60xx-wcss-pil";
			qcom,halt-regs = <0x21 0xa000 0xd000 0x00>;
			firmware = "IPQ6018/q6_fw.mdt";
			interrupts-extended = <0x01 0x00 0x145 0x01 0x15 0x00 0x00 0x15 0x01 0x00 0x15 0x02 0x00 0x15 0x03 0x00>;
			qcom,smem-states = <0x16 0x00 0x16 0x01>;
			reg-names = "qdsp6\0rmb";
			qca,extended-intc;
			resets = <0x03 0x7f 0x03 0x16 0x03 0x17>;
			qca,auto-restart;
			qcom,wcss-aon-reset-quirk;

			glink-edge {
				global_timer = <0x4a5000>;
				mboxes = <0x22 0x08>;
				qcom,remote-pid = <0x01>;
				interrupts = <0x00 0x141 0x01>;

				rpm_requests {
					qcom,glink-channels = "IPCRTR";
				};
			};
		};

		qcom,glink-smem-native-xprt-modem@4AA00000 {
			reg = <0x4aa00000 0x100000 0xb111008 0x04>;
			compatible = "qcom,glink-smem-native-xprt";
			label = "mpss";
			smem-entry = <0x1de 0x1df 0x1e0>;
			smem-entry-names = "ch\0tx_fifo\0rx_fifo";
			qcom,irq-mask = <0x100>;
			qcom,subsys-id = <0x01>;
			interrupts = <0x00 0x141 0x01>;
			reg-names = "smem\0irq-reg-base";
		};

		dma@7884000 {
			linux,phandle = <0x0d>;
			reg = <0x7884000 0x2b000>;
			phandle = <0x0d>;
			clocks = <0x03 0x43>;
			compatible = "qcom,bam-v1.7.0";
			#dma-cells = <0x01>;
			qcom,ee = <0x00>;
			interrupts = <0x00 0xee 0x00>;
			clock-names = "bam_clk";
		};

		watchdog@b017000 {
			timeout-sec = <0x1e>;
			wdt-max-timeout = <0x20>;
			reg = <0xb017000 0x1000>;
			clocks = <0x1f>;
			interrupt-names = "bark_irq";
			compatible = "qcom,kpss-wdt-ipq6018";
			interrupts = <0x00 0x03 0x00>;
			reg-names = "kpss_wdt";
		};

		cti@6011000 {
			reg = <0x6011000 0x1000>;
			clocks = <0x03 0xbf 0x03 0xbe>;
			compatible = "arm,coresight-cti";
			coresight-name = "coresight-cti1";
			reg-names = "cti-base";
			clock-names = "core_clk\0core_a_clk";
		};

		syscon@1905000 {
			linux,phandle = <0x0f>;
			reg = <0x1905000 0x8000>;
			phandle = <0x0f>;
			compatible = "syscon";
		};

		dp2 {
			local-mac-address = [1c 59 74 50 00 19];
			device_type = "network";
			qcom,mactype = <0x00>;
			reg = <0x3a001200 0x200>;
			qcom,phy-mdio-addr = <0x00>;
			compatible = "qcom,nss-dp";
			qcom,id = <0x01>;
			qcom,link-poll = <0x01>;
			phy-mode = "sgmii";
		};

		rpm_etm0 {
			compatible = "qcom,coresight-remote-etm";
			coresight-name = "coresight-rpm-etm0";
			qcom,inst-id = <0x04>;

			port {

				endpoint {
					linux,phandle = <0x32>;
					phandle = <0x32>;
					remote-endpoint = <0x45>;
				};
			};
		};

		clock-controller@b198000 {
			linux,phandle = <0x50>;
			reg = <0xb198000 0x1000>;
			phandle = <0x50>;
			compatible = "qcom,arm-cortex-acc";
		};

		spi@78b5000 {
			dma-names = "tx\0rx";
			#size-cells = <0x00>;
			dmas = <0x0d 0x0c 0x0d 0x0d>;
			reg = <0x78b5000 0x600>;
			clocks = <0x03 0x45 0x03 0x43>;
			compatible = "qcom,spi-qup-v2.2.1";
			#address-cells = <0x01>;
			interrupts = <0x00 0x5f 0x00>;
			spi-max-frequency = <0x2faf080>;
			clock-names = "core\0iface";
			status = "disabled";
		};

		qcom,glink-rpm-native-xprt@60000 {
			reg = <0x60000 0x6000 0xb111008 0x04>;
			compatible = "qcom,glink-rpm-native-xprt";
			label = "rpm";
			qcom,irq-mask = <0x01>;
			qcom,subsys-id = <0x06>;
			interrupts = <0x00 0xa8 0x01>;
			reg-names = "msgram\0irq-reg-base";
			status = "ok";
		};

		dp3 {
			local-mac-address = [00 00 00 00 00 00];
			device_type = "network";
			qcom,mactype = <0x00>;
			reg = <0x3a001400 0x200>;
			qcom,phy-mdio-addr = <0x03>;
			compatible = "qcom,nss-dp";
			qcom,id = <0x04>;
			qcom,link-poll = <0x01>;
			phy-mode = "sgmii";
		};

		qcom,rpm-log@29fc00 {
			qcom,offset-log-len = <0x28>;
			qcom,offset-log-len-mask = <0x2c>;
			qcom,offset-page-buffer-addr = <0x24>;
			qcom,offset-page-indices = <0x38>;
			reg = <0x29fc00 0x4000>;
			compatible = "qcom,rpm-log";
			qcom,rpm-addr-phys = <0x200000>;
			qcom,offset-version = <0x04>;
		};

		cti@6019000 {
			reg = <0x6019000 0x1000>;
			clocks = <0x03 0xbf 0x03 0xbe>;
			compatible = "arm,coresight-cti";
			coresight-name = "coresight-cti9";
			reg-names = "cti-base";
			clock-names = "core_clk\0core_a_clk";
		};

		cti@610c000 {
			reg = <0x610c000 0x1000>;
			clocks = <0x03 0xbf 0x03 0xbe>;
			compatible = "arm,coresight-cti";
			coresight-name = "coresight-cti-rpm-cpu0";
			reg-names = "cti-base";
			clock-names = "core_clk\0core_a_clk";
		};

		cti@6012000 {
			reg = <0x6012000 0x1000>;
			clocks = <0x03 0xbf 0x03 0xbe>;
			compatible = "arm,coresight-cti";
			coresight-name = "coresight-cti2";
			reg-names = "cti-base";
			clock-names = "core_clk\0core_a_clk";
		};

		timer {
			always-on;
			compatible = "arm,armv8-timer";
			clock-frequency = <0x16e3600>;
			interrupts = <0x01 0x02 0xf08 0x01 0x03 0xf08 0x01 0x04 0xf08 0x01 0x01 0xf08>;
		};

		cti@6014000 {
			reg = <0x6014000 0x1000>;
			clocks = <0x03 0xbf 0x03 0xbe>;
			compatible = "arm,coresight-cti";
			coresight-name = "coresight-cti4";
			reg-names = "cti-base";
			clock-names = "core_clk\0core_a_clk";
		};

		csr@6001000 {
			qcom,blk-size = <0x01>;
			reg = <0x6001000 0x1000>;
			clocks = <0x03 0xbf 0x03 0xbe>;
			compatible = "qcom,coresight-csr";
			coresight-name = "coresight-csr";
			reg-names = "csr-base";
			clock-names = "core_clk\0core_a_clk";
		};

		smp2p-wcss {
			qcom,ipc = <0x10 0x08 0x09>;
			qcom,local-pid = <0x00>;
			interrupt-parent = <0x01>;
			qcom,smem = <0x1b3 0x1ac>;
			qcom,remote-pid = <0x01>;
			compatible = "qcom,smp2p";
			interrupts = <0x00 0x142 0x01>;

			slave-kernel {
				linux,phandle = <0x15>;
				phandle = <0x15>;
				#interrupt-cells = <0x02>;
				qcom,entry-name = "slave-kernel";
				interrupt-controller;
			};

			master-kernel {
				linux,phandle = <0x16>;
				phandle = <0x16>;
				qcom,entry-name = "master-kernel";
				qcom,smp2p-feature-ssr-ack;
				#qcom,smem-state-cells = <0x01>;
			};
		};

		qcom,smem@4AA00000 {
			hwlocks = <0x12 0x00>;
			memory-region = <0x11>;
			compatible = "qcom,smem";
		};

		dp4 {
			local-mac-address = [00 00 00 00 00 00];
			device_type = "network";
			qcom,mactype = <0x00>;
			reg = <0x3a001600 0x200>;
			qcom,phy-mdio-addr = <0x02>;
			compatible = "qcom,nss-dp";
			qcom,id = <0x03>;
			qcom,link-poll = <0x01>;
			phy-mode = "sgmii";
		};

		usb2@7000000 {
			ranges;
			#size-cells = <0x01>;
			reg = <0x70f8800 0x100 0x7000000 0xcd00>;
			qca,host = <0x01>;
			clocks = <0x03 0xa3 0x03 0xa6 0x03 0xa4 0x03 0xa5>;
			compatible = "qcom,ipq6018-dwc3";
			#address-cells = <0x01>;
			assigned-clocks = <0x03 0xa3 0x03 0xa4>;
			assigned-clock-rates = <0x7f27450 0x16e3600>;
			reg-names = "qscratch_base\0dwc3_base";
			clock-names = "master\0sleep\0mock_utmi\0cfg_ahb_clk";
			status = "ok";

			dwc3@7000000 {
				snps,nominal-elastic-buffer;
				snps,is-utmi-l1-suspend;
				snps,dis_ep_cache_eviction;
				snps,dis_u3_susphy_quirk;
				snps,hird-threshold = [00];
				usb-phy = <0x0a>;
				reg = <0x7000000 0xcd00>;
				snps,quirk-ref-clock-period = <0x29>;
				snps,usb3-u1u2-disable;
				snps,quirk-ref-clock-adjustment = <0xa87f0>;
				tx-fifo-resize;
				dr_mode = "host";
				compatible = "snps,dwc3";
				snps,dis_u2_susphy_quirk;
				interrupts = <0x00 0x63 0x00>;
			};
		};

		cti@601a000 {
			reg = <0x601a000 0x1000>;
			clocks = <0x03 0xbf 0x03 0xbe>;
			compatible = "arm,coresight-cti";
			coresight-name = "coresight-cti10";
			reg-names = "cti-base";
			clock-names = "core_clk\0core_a_clk";
		};

		dp5 {
			local-mac-address = [00 00 00 00 00 00];
			device_type = "network";
			qcom,mactype = <0x00>;
			reg = <0x3a001800 0x200>;
			qcom,phy-mdio-addr = <0x04>;
			compatible = "qcom,nss-dp";
			qcom,id = <0x05>;
			qcom,link-poll = <0x01>;
			phy-mode = "sgmii";
		};

		tpda@6004000 {
			qcom,tpda-atid = <0x40>;
			reg = <0x6004000 0x1000>;
			clocks = <0x03 0xbf 0x03 0xbe>;
			compatible = "qcom,coresight-tpda";
			qcom,cmb-elem-size = <0x00 0x20>;
			coresight-name = "coresight-tpda";
			reg-names = "tpda-base";
			clock-names = "core_clk\0core_a_clk";

			ports {
				#size-cells = <0x00>;
				#address-cells = <0x01>;

				port@0 {
					reg = <0x00>;

					endpoint {
						linux,phandle = <0x30>;
						phandle = <0x30>;
						remote-endpoint = <0x48>;
					};
				};

				port@1 {
					reg = <0x00>;

					endpoint {
						linux,phandle = <0x4a>;
						slave-mode;
						phandle = <0x4a>;
						remote-endpoint = <0x49>;
					};
				};
			};
		};

		syscon@1945000 {
			linux,phandle = <0x21>;
			reg = <0x1945000 0xe000>;
			phandle = <0x21>;
			compatible = "syscon";
		};

		clock-controller@b188000 {
			linux,phandle = <0x4d>;
			reg = <0xb188000 0x1000>;
			phandle = <0x4d>;
			compatible = "qcom,arm-cortex-acc";
		};

		arm,smmu@1E00000 {
			linux,phandle = <0x02>;
			qcom,skip-init;
			reg = <0x1e00000 0x40000>;
			phandle = <0x02>;
			#global-interrupts = <0x01>;
			compatible = "arm,smmu-v2";
			interrupts = <0x00 0x29 0x04 0x00 0x46 0x04 0x00 0x47 0x04 0x00 0x49 0x04 0x00 0xf0 0x04 0x00 0xf1 0x04 0x00 0xf2 0x04 0x00 0xf5 0x04 0x00 0xf6 0x04 0x00 0xf7 0x04 0x00 0xf8 0x04 0x00 0xf9 0x04 0x00 0xfa 0x04 0x00 0xfb 0x04 0x00 0xfc 0x04 0x00 0xfd 0x04 0x00 0xfe 0x04 0x00 0xff 0x04 0x00 0x35 0x04 0x00 0x36 0x04 0x00 0x3a 0x04 0x00 0x3c 0x04 0x00 0x3d 0x04 0x00 0x4c 0x04 0x00 0x4d 0x04 0x00 0x50 0x04 0x00 0x5e 0x04 0x00 0x65 0x04 0x00 0x66 0x04 0x00 0x67 0x04 0x00 0x68 0x04 0x00 0x69 0x04 0x00 0x6a 0x04>;
			#iommu-cells = <0x01>;
			status = "disabled";
		};

		funnel@6130000 {
			arm,primecell-periphid = <0x3b908>;
			reg = <0x6130000 0x1000>;
			clocks = <0x03 0xbf 0x03 0xbe>;
			compatible = "arm,primecell";
			coresight-name = "coresight-funnel-mm";
			reg-names = "funnel-base";
			clock-names = "apb_pclk\0core_a_clk";

			ports {
				#size-cells = <0x00>;
				#address-cells = <0x01>;

				port@0 {
					reg = <0x00>;

					endpoint {
						linux,phandle = <0x2f>;
						phandle = <0x2f>;
						remote-endpoint = <0x35>;
					};
				};
			};
		};

		tmc@6048000 {
			arm,primecell-periphid = <0x3b961>;
			arm,buffer-size = <0x100000>;
			reg = <0x6048000 0x1000 0x6064000 0x15000>;
			clocks = <0x03 0xbf 0x03 0xbe>;
			interrupt-names = "byte-cntr-irq";
			coresight-ctis = <0x25 0x26>;
			compatible = "arm,primecell";
			arm,sg-enable;
			interrupts = <0x00 0xa6 0x00>;
			coresight-name = "coresight-tmc-etr";
			reg-names = "tmc-base\0bam-base";
			memory_region = <0x18>;
			clock-names = "apb_pclk\0core_a_clk";

			port {

				endpoint {
					linux,phandle = <0x28>;
					slave-mode;
					phandle = <0x28>;
					remote-endpoint = <0x27>;
				};
			};
		};

		pinctrl@1000000 {
			linux,phandle = <0x0c>;
			gpio-controller;
			reg = <0x1000000 0x300000>;
			phandle = <0x0c>;
			#interrupt-cells = <0x02>;
			compatible = "qcom,ipq6018-pinctrl";
			#gpio-cells = <0x02>;
			interrupts = <0x00 0xd0 0x00>;
			interrupt-controller;

			button_pins {
				linux,phandle = <0x4b>;
				phandle = <0x4b>;

				reset_button {
					function = "gpio";
					pins = "gpio19";
					bias-pull-up;
					drive-strength = <0x08>;
				};
			};

			mdio_pinmux {
				linux,phandle = <0x20>;
				phandle = <0x20>;

				mux_0 {
					function = "mdc";
					pins = "gpio64";
					bias-pull-up;
					drive-strength = <0x08>;
				};

				mux_2 {
					function = "gpio";
					pins = "gpio75";
					bias-pull-up;
				};

				mux_1 {
					function = "mdio";
					pins = "gpio65";
					bias-pull-up;
					drive-strength = <0x08>;
				};
			};

			leds_pins {
				linux,phandle = <0x4c>;
				phandle = <0x4c>;

				led_rssi2 {
					function = "gpio";
					pins = "gpio22";
					bias-pull-down;
					drive-strength = <0x08>;
				};

				led_system {
					function = "gpio";
					pins = "gpio34";
					bias-pull-down;
					drive-strength = <0x08>;
				};

				led_rssi4 {
					function = "gpio";
					pins = "gpio24";
					bias-pull-down;
					drive-strength = <0x08>;
				};

				led_5g {
					function = "gpio";
					pins = "gpio35";
					bias-pull-down;
					drive-strength = <0x08>;
				};

				led_2g {
					function = "gpio";
					pins = "gpio37";
					bias-pull-down;
					drive-strength = <0x08>;
				};

				sfp_disable {
					function = "gpio";
					pins = "gpio26";
					bias-pull-up;
					drive-strength = <0x08>;
				};

				led_rssi1 {
					function = "gpio";
					pins = "gpio18";
					bias-pull-down;
					drive-strength = <0x08>;
				};

				led_rssi3 {
					function = "gpio";
					pins = "gpio23";
					bias-pull-down;
					drive-strength = <0x08>;
				};
			};

			qpic_pins {

				data_4 {
					function = "qpic_pad4";
					pins = "gpio5";
					bias-pull-down;
					drive-strength = <0x08>;
				};

				data_2 {
					function = "qpic_pad2";
					pins = "gpio13";
					bias-pull-down;
					drive-strength = <0x08>;
				};

				data_6 {
					function = "qpic_pad6";
					pins = "gpio7";
					bias-pull-down;
					drive-strength = <0x08>;
				};

				data_0 {
					function = "qpic_pad0";
					pins = "gpio15";
					bias-pull-down;
					drive-strength = <0x08>;
				};

				data_5 {
					function = "qpic_pad5";
					pins = "gpio6";
					bias-pull-down;
					drive-strength = <0x08>;
				};

				data_3 {
					function = "qpic_pad3";
					pins = "gpio14";
					bias-pull-down;
					drive-strength = <0x08>;
				};

				data_7 {
					function = "qpic_pad7";
					pins = "gpio8";
					bias-pull-down;
					drive-strength = <0x08>;
				};

				data_1 {
					function = "qpic_pad1";
					pins = "gpio12";
					bias-pull-down;
					drive-strength = <0x08>;
				};

				qpic_pad {
					function = "qpic_pad";
					pins = "gpio1\0gpio3\0gpio4\0gpio10\0gpio11\0gpio17";
					bias-pull-down;
					drive-strength = <0x08>;
				};
			};

			uart_pins {
				linux,phandle = <0x04>;
				phandle = <0x04>;

				mux {
					function = "blsp2_uart";
					pins = "gpio44\0gpio45";
					bias-pull-down;
					drive-strength = <0x08>;
				};
			};

			hsuart_pins {

				mux {
					function = "blsp1_uart";
					pins = "gpio71\0gpio72\0gpio69\0gpio70";
					drive-strength = <0x08>;
					bias-disable;
				};
			};

			i2c_1_pins {
				linux,phandle = <0x0e>;
				phandle = <0x0e>;

				mux {
					function = "blsp2_i2c";
					pins = "gpio42\0gpio43";
					bias-pull-down;
					drive-strength = <0x08>;
				};
			};
		};

		cti@619a000 {
			cpu = <0x41>;
			reg = <0x619a000 0x1000>;
			clocks = <0x03 0xbf 0x03 0xbe>;
			compatible = "arm,coresight-cti";
			coresight-name = "coresight-cti-cpu2";
			reg-names = "cti-base";
			clock-names = "core_clk\0core_a_clk";
		};

		qcom,ipc_router {
			qcom,node-id = <0x01>;
			compatible = "qcom,ipc_router";
		};

		sdhci_sd@7804000 {
			qcom,dedicated-io = <0x01>;
			qcom,msm-bus,num-paths = <0x01>;
			qcom,vdd-io-voltage-level = <0x1b7740 0x2d0370>;
			qcom,vdd-voltage-level = <0x2d0370 0x2d0370>;
			qcom,msm-bus,vectors-KBps = <0x51 0x200 0x00 0x00 0x51 0x200 0x416 0xc80 0x51 0x200 0xcc3e 0x27100 0x51 0x200 0xff50 0x30d40 0x51 0x200 0x1fe9e 0x61a80 0x51 0x200 0x3fd3e 0xc3500 0x51 0x200 0x3fd3e 0xc3500 0x51 0x200 0x146cc2 0x3e8000>;
			qcom,disable-aggressive-pm;
			qcom,msm-bus,num-cases = <0x08>;
			qcom,msm-bus,name = "sdhc2";
			qcom,vdd-io-current-level = <0xc8 0x55f0>;
			qcom,vdd-current-level = <0x3a98 0x61a80>;
			reg = <0x7804000 0x1000>;
			qcom,bus-speed-mode = "HS200_1p8v\0DDR_1p8v";
			qcom,max_clk = <0xb71b000>;
			clocks = <0x03 0x8b 0x03 0x8c>;
			interrupt-names = "hc_irq\0pwr_irq";
			qcom,bus-width = <0x04>;
			compatible = "qcom,sdhci-msm-v5";
			qcom,vdd-io-lpm-sup;
			qcom,large-address-bus;
			qcom,bus-bw-vectors-bps = <0x00 0x61a80 0x1312d00 0x17d7840 0x2faf080 0x5f5e100 0xbebc200 0xffffffff>;
			qcom,vdd-io-always-on;
			interrupts = <0x00 0x7b 0x00 0x00 0x8a 0x00>;
			qcom,cpu-dma-latency-us = <0x2bd>;
			reg-names = "hc_mem";
			qcom,clk-rates = <0x61a80 0x17d7840 0x2faf080 0x5f5e100 0xb71b000>;
			clock-names = "iface_clk\0core_clk";
			status = "disabled";
		};

		interrupt-controller@b000000 {
			linux,phandle = <0x01>;
			reg = <0xb000000 0x1000 0xb002000 0x1000>;
			phandle = <0x01>;
			#interrupt-cells = <0x03>;
			compatible = "qcom,msm-qgic2";
			interrupt-controller;
		};

		smp2p-adsp {
			qcom,ipc = <0x10 0x08 0x15>;
			qcom,local-pid = <0x00>;
			interrupt-parent = <0x01>;
			qcom,smem = <0x1bb 0x1ad>;
			qcom,remote-pid = <0x02>;
			compatible = "qcom,smp2p";
			interrupts = <0x00 0x1a 0x01>;
			status = "disabled";

			slave-kernel {
				linux,phandle = <0x1b>;
				phandle = <0x1b>;
				#interrupt-cells = <0x02>;
				qcom,entry-name = "slave-kernel";
				interrupt-controller;
			};

			master-kernel {
				linux,phandle = <0x1c>;
				phandle = <0x1c>;
				qcom,entry-name = "master-kernel";
				qcom,smp2p-feature-ssr-ack;
				#qcom,smem-state-cells = <0x01>;
			};
		};

		qcom_q6v6_adsp@AB00000 {
			qcom,smem-state-names = "shutdown\0stop";
			interrupt-names = "wdog\0fatal\0ready\0handover\0stop-ack";
			compatible = "qcom,ipq6018-adsp-pil";
			interrupts-extended = <0x01 0x00 0x1e 0x01 0x1b 0x00 0x00 0x1b 0x01 0x00 0x1b 0x02 0x00 0x1b 0x03 0x00>;
			qcom,smem-states = <0x1c 0x00 0x1c 0x01>;
			status = "disabled";

			glink-edge {
				mboxes = <0x23 0x08>;
				qcom,remote-pid = <0x02>;
				interrupts = <0x00 0x18 0x01>;

				qcom,msm_fastrpc_rpmsg {
					qcom,glink-channels = "fastrpcglink-apps-dsp";
					compatible = "qcom,msm-fastrpc-rpmsg";
					qcom,intents = <0x64 0x40>;
				};

				rpm_requests {
					qcom,glink-channels = "IPCRTR";
				};
			};
		};

		clock-controller@b1a8000 {
			linux,phandle = <0x51>;
			reg = <0xb1a8000 0x1000>;
			phandle = <0x51>;
			compatible = "qcom,arm-cortex-acc";
		};

		qca,tzlog {
			qca,hyp-enabled;
			hyp-scm-cmd-id = <0x0a>;
			qca,tzbsp-diag-buf-size = <0x3000>;
			compatible = "qca,tzlog_ipq6018";
			qca,tzbsp-diag-buf-start = <0x4a7df000>;
			interrupts = <0x00 0xf4 0x01>;
		};

		qcom,apss_clk@b111000 {
			#reset-cells = <0x01>;
			linux,phandle = <0x4f>;
			reg = <0xb111000 0x6000>;
			#clock-cells = <0x01>;
			phandle = <0x4f>;
			compatible = "qcom,apss-ipq6018";
		};

		phy@84000 {
			linux,phandle = <0x0b>;
			#phy-cells = <0x00>;
			qcom,qmp-pcie-phy-init-seq = <0x840 0x03 0x1c 0x7d 0x20 0x01 0x24 0x0a 0x28 0x05 0x2c 0x08 0x30 0x04 0x3c 0x18 0x40 0x90 0x44 0x02 0x48 0x07 0x50 0x0f 0x54 0xd4 0x58 0x14 0x60 0xaa 0x64 0x29 0x74 0x0f 0xffffffff 0x01 0x80 0x09 0x84 0x09 0x88 0x16 0x8c 0x16 0x90 0x28 0x94 0x28 0xa4 0x01 0xa8 0x08 0xb0 0x20 0xc4 0x42 0xcc 0x68 0xd0 0x53 0xd8 0xab 0xdc 0xaa 0xe0 0x02 0xe4 0x55 0xe8 0x55 0xec 0x05 0x100 0xa0 0x108 0xa0 0x124 0x24 0x128 0x02 0x12c 0xb4 0x130 0x03 0x16c 0x32 0x170 0x01 0x184 0x00 0x18c 0x06 0x194 0x05 0x1b4 0x08 0x23c 0x02 0x284 0x06 0x29c 0x12 0x408 0x0c 0x414 0x02 0x434 0x7f 0x444 0x70 0x4ec 0x61 0x4f0 0x04 0x4f4 0x1e 0x4f8 0xc0 0x4fc 0x00 0x510 0x73 0x514 0x80 0x518 0x1c 0x51c 0x03 0x524 0x14 0x570 0xf0 0x574 0x01 0x578 0x2f 0x57c 0xd3 0x580 0x40 0x584 0x01 0x588 0x02 0x58c 0xc8 0x590 0x09 0x594 0xb1 0x598 0x00 0x59c 0x02 0x5a0 0xc8 0x5a4 0x09 0x5a8 0xb1 0x5b4 0x04 0x898 0x01 0x8dc 0x0d 0x96c 0x10 0x988 0xaa 0x9a4 0x01 0x9d8 0x01 0x9ec 0x01 0xc0c 0x0d 0xc14 0x07 0xc1c 0xc1 0xc40 0x01 0xc48 0x01 0xc90 0x00 0xca0 0x11 0xcbc 0x00 0xce0 0x58 0x800 0x00 0x844 0x03>;
			reg = <0x84000 0x1000>;
			phandle = <0x0b>;
			clocks = <0x03 0x87>;
			reset-names = "phy\0phy_phy";
			compatible = "qca,pcie-qmp-phy-gen3";
			resets = <0x03 0x45 0x03 0x46>;
			phy-type = "gen3";
			clock-names = "pipe_clk";
			status = "disabled";
		};

		dcc@b3000 {
			no_xpu_support;
			reg = <0xb3000 0x1000 0xb4000 0x800 0x4a2000 0x08>;
			qca,save-reg;
			clocks = <0x03 0xc4>;
			compatible = "qca,dcc";
			reg-names = "dcc-base\0dcc-ram-base\0gcnt_lo_hi";
			clock-names = "dcc_clk";
			status = "ok";
		};

		etm@619c000 {
			arm,primecell-periphid = <0x3b95d>;
			cpu = <0x3d>;
			reg = <0x619c000 0x1000>;
			clocks = <0x03 0xbf 0x03 0xbe>;
			compatible = "arm,primecell";
			coresight-name = "coresight-etm0";
			clock-names = "apb_pclk\0core_a_clk";

			port {

				endpoint {
					linux,phandle = <0x39>;
					phandle = <0x39>;
					remote-endpoint = <0x3e>;
				};
			};
		};

		pwm {
			src-freq = <0x5f5e100>;
			reg = <0x1941010 0x20>;
			clocks = <0x03 0xc1>;
			compatible = "qca,ipq6018-pwm";
			pwm-base-index = <0x00>;
			used-pwm-indices = <0x01 0x01 0x01 0x01>;
			clock-names = "core";
			status = "disabled";
		};

		sdhci@7804000 {
			qcom,dedicated-io = <0x01>;
			qcom,msm-bus,num-paths = <0x01>;
			qcom,vdd-io-voltage-level = <0x1b7740 0x1b7740>;
			qcom,vdd-voltage-level = <0x2c4020 0x2c4020>;
			qcom,msm-bus,vectors-KBps = <0x4e 0x200 0x00 0x00 0x4e 0x200 0x416 0xc80 0x4e 0x200 0xcc3e 0x27100 0x4e 0x200 0xff50 0x30d40 0x4e 0x200 0x1fe9e 0x61a80 0x4e 0x200 0x3fd3e 0xc3500 0x4e 0x200 0x3fd3e 0xc3500 0x4e 0x200 0x3fd3e 0xc3500 0x4e 0x200 0x146cc2 0x3e8000>;
			qcom,disable-aggressive-pm;
			qcom,ice-clk-rates = <0x9896800 0x12646790>;
			qcom,msm-bus,num-cases = <0x09>;
			qcom,msm-bus,name = "sdhc1";
			qcom,vdd-io-current-level = <0xc8 0x4f588>;
			sdhc-msm-crypto = <0x1e>;
			qcom,vdd-current-level = <0xc8 0x8b290>;
			reg = <0x7804000 0x1000 0x7805000 0x1000>;
			qcom,bus-speed-mode = "HS200_1p8v\0DDR_1p8v";
			qcom,max_clk = <0xb71b000>;
			clocks = <0x03 0x8b 0x03 0x8c 0x03 0xc3>;
			interrupt-names = "hc_irq\0pwr_irq";
			qcom,bus-width = <0x08>;
			compatible = "qcom,sdhci-msm-v5";
			qcom,vdd-io-lpm-sup;
			qcom,large-address-bus;
			qcom,nonremovable;
			qcom,bus-bw-vectors-bps = <0x00 0x61a80 0x1312d00 0x17d7840 0x2faf080 0x5f5e100 0xbebc200 0x17d78400 0xffffffff>;
			qcom,vdd-io-always-on;
			interrupts = <0x00 0x7b 0x00 0x00 0x8a 0x00>;
			qcom,cpu-dma-latency-us = <0x2bd>;
			reg-names = "hc_mem\0cmdq_mem";
			qcom,clk-rates = <0x61a80 0x17d7840 0x2faf080 0x5f5e100 0xb71b000>;
			clock-names = "iface_clk\0core_clk\0ice_core_clk";
			status = "ok";
		};

		spi@78b6000 {
			dma-names = "tx\0rx";
			#size-cells = <0x00>;
			dmas = <0x0d 0x0e 0x0d 0x0f>;
			reg = <0x78b6000 0x600>;
			clocks = <0x03 0x47 0x03 0x43>;
			compatible = "qcom,spi-qup-v2.2.1";
			#address-cells = <0x01>;
			interrupts = <0x00 0x60 0x00>;
			spi-max-frequency = <0x2faf080>;
			clock-names = "core\0iface";
			status = "disabled";
		};

		pci@20000000 {
			interrupt-map-mask = <0x00 0x00 0x00 0x07>;
			device_type = "pci";
			num-lanes = <0x01>;
			ranges = <0x81000000 0x00 0x20200000 0x20200000 0x00 0x100000 0x82000000 0x00 0x20300000 0x20300000 0x00 0x10000000>;
			#size-cells = <0x02>;
			bus-range = <0x00 0xff>;
			reg = <0x20000000 0xf1d 0x20000f20 0xa8 0x20001000 0x1000 0x80000 0x2000 0x20100000 0x1000>;
			clocks = <0x03 0xbb 0x03 0x85 0x03 0x86 0x03 0x83 0x03 0x84 0x03 0xc6 0x03 0xc7>;
			phy-names = "pciephy";
			interrupt-names = "msi";
			#interrupt-cells = <0x01>;
			reset-names = "pipe\0sleep\0sticky\0axi_m\0axi_s\0ahb\0axi_m_sticky\0axi_s_sticky";
			compatible = "qcom,pcie-ipq6018";
			#address-cells = <0x03>;
			linux,pci-domain = <0x00>;
			phys = <0x0b>;
			perst-gpio = <0x0c 0x3c 0x01>;
			interrupts = <0x00 0x34 0x00>;
			reg-names = "dbi\0elbi\0dm_iatu\0parf\0config";
			resets = <0x03 0x60 0x03 0x61 0x03 0x62 0x03 0x63 0x03 0x64 0x03 0x65 0x03 0x66 0x03 0x67>;
			interrupt-map = <0x00 0x00 0x00 0x01 0x01 0x00 0x4b 0x04 0x00 0x00 0x00 0x02 0x01 0x00 0x4e 0x04 0x00 0x00 0x00 0x03 0x01 0x00 0x4f 0x04 0x00 0x00 0x00 0x04 0x01 0x00 0x53 0x04>;
			clock-names = "sys_noc\0axi_m\0axi_s\0ahb\0aux\0axi_bridge\0rchng";
			status = "disabled";

			pcie0_rp {
				reg = <0x00 0x00 0x00 0x00 0x00>;
			};
		};

		etm@619d000 {
			arm,primecell-periphid = <0x3b95d>;
			cpu = <0x3f>;
			reg = <0x619d000 0x1000>;
			clocks = <0x03 0xbf 0x03 0xbe>;
			compatible = "arm,primecell";
			coresight-name = "coresight-etm1";
			clock-names = "apb_pclk\0core_a_clk";

			port {

				endpoint {
					linux,phandle = <0x3a>;
					phandle = <0x3a>;
					remote-endpoint = <0x40>;
				};
			};
		};

		tpdm@6110000 {
			reg = <0x6110000 0x1000>;
			clocks = <0x03 0xbf 0x03 0xbe>;
			compatible = "qcom,coresight-tpdm";
			coresight-name = "coresight-tpdm-dcc";
			reg-names = "tpdm-base";
			clock-names = "core_clk\0core_a_clk";

			port {

				endpoint {
					linux,phandle = <0x49>;
					phandle = <0x49>;
					remote-endpoint = <0x4a>;
				};
			};
		};

		dma@7984000 {
			linux,phandle = <0x06>;
			reg = <0x7984000 0x1a000>;
			phandle = <0x06>;
			clocks = <0x03 0x89>;
			compatible = "qcom,bam-v1.7.0";
			#dma-cells = <0x01>;
			qcom,ee = <0x00>;
			interrupts = <0x00 0x92 0x00>;
			clock-names = "bam_clk";
			status = "ok";
		};

		cti@601c000 {
			reg = <0x601c000 0x1000>;
			clocks = <0x03 0xbf 0x03 0xbe>;
			compatible = "arm,coresight-cti";
			coresight-name = "coresight-cti12";
			reg-names = "cti-base";
			clock-names = "core_clk\0core_a_clk";
		};

		hwevent@6101000 {
			reg = <0x6101000 0x148 0x6101fb0 0x04 0x6121000 0x148 0x6121fb0 0x04 0x6131000 0x148 0x6131fb0 0x04 0x6130fb0 0x04 0x6130000 0x148 0x6041fb0 0x04 0x6041000 0x148>;
			clocks = <0x03 0xbf 0x03 0xbe>;
			compatible = "qcom,coresight-hwevent";
			coresight-name = "coresight-hwevent";
			reg-names = "center-wrapper-mux\0center-wrapper-lockaccess\0right-wrapper-mux\0right-wrapper-lockaccess\0mm-wrapper-mux\0mm-wrapper-lockaccess\0mm-fun-lockaccess\0mm-fun\0in-fun-lockaccess\0in-fun";
			clock-names = "core_clk\0core_a_clk";
		};

		serial@78af000 {
			reg = <0x78af000 0x200>;
			clocks = <0x03 0x50 0x03 0x43>;
			compatible = "qcom,msm-uartdm-v1.4\0qcom,msm-uartdm";
			interrupts = <0x00 0x6b 0x04>;
			clock-names = "core\0iface";
			status = "disabled";
		};

		dp1 {
			local-mac-address = [1c 59 74 50 00 18];
			device_type = "network";
			qcom,mactype = <0x00>;
			reg = <0x3a001000 0x200>;
			qcom,phy-mdio-addr = <0x01>;
			compatible = "qcom,nss-dp";
			qcom,id = <0x02>;
			qcom,link-poll = <0x01>;
			phy-mode = "sgmii";
		};

		qcom,ipc_router_modem_xprt {
			qcom,xprt-linkid = <0x01>;
			qcom,ch-name = "IPCRTR";
			qcom,glink-xprt = "smem";
			compatible = "qcom,ipc_router_glink_xprt";
			qcom,fragmented-data;
			qcom,xprt-remote = "mpss";
			qcom,xprt-version = <0x01>;
		};

		q6v6_adsp@AB00000 {
			qcom,smem-state-names = "shutdown\0stop";
			qca,sec-reset-cmd = <0x18>;
			reg = <0xab00000 0x4040 0x181f000 0x04 0xa000000 0x48000 0x1954010 0x20>;
			clocks = <0x03 0xf5 0x03 0xf6 0x03 0xe4 0x03 0xe5 0x03 0xe6 0x03 0xe7 0x03 0xe8 0x03 0xe9 0x03 0xea 0x03 0xeb 0x03 0xef>;
			interrupt-names = "wdog\0qcom,gpio-err-fatal\0qcom,gpio-err-ready\0qcom,gpio-stop-ack";
			compatible = "qca,q6v6-adsp-rproc";
			qca,secure;
			firmware = "IPQ6018/adsp.mdt";
			interrupts-extended = <0x01 0x00 0x1e 0x01 0x1b 0x00 0x00 0x1b 0x01 0x00 0x1b 0x03 0x00>;
			qcom,smem-states = <0x1c 0x00 0x1c 0x01>;
			reg-names = "adsp-base\0gcc-adsp-bcr-base\0adsp-cc-base\0tcsr-base";
			qca,extended-intc;
			clock-names = "mem_noc_lpass_clk\0snoc_lpass_cfg_clk\0lpass_core_axim_clk\0lpass_snoc_cfg_clk\0lpass_q6_axim_clk\0lpass_q6_atbm_at_clk\0lpass_q6_pclkdbg_clk\0lpass_q6ss_tsctr_1to2_clk\0lpass_q6ss_trig_clk\0lpass_tbu_clk\0pcnoc_lpass_clk";
			status = "disabled";
		};

		hwlock@1905000 {
			linux,phandle = <0x12>;
			phandle = <0x12>;
			compatible = "qcom,tcsr-mutex";
			syscon = <0x0f 0x00 0x80>;
			#hwlock-cells = <0x01>;
		};

		wifi1@f00000 {
			qrtr_node_id = <0x20>;
			mhi,timeout = <0x2710>;
			#size-cells = <0x00>;
			qcom,wlan-ramdump-dynamic = <0x400000>;
			compatible = "qcom,cnss-qcn9000";
			#address-cells = <0x01>;
			qca,auto-restart;
			mhi,max-channels = <0x1e>;
			status = "disabled";

			mhi_devices {

				mhi_qrtr {
					mhi,chan = "IPCR";
					qcom,net-id = <0x00>;
				};
			};

			mhi_events {

				mhi_event@0 {
					mhi,msi = <0x01>;
					mhi,brstmode = <0x02>;
					mhi,data-type = <0x01>;
					mhi,intmod = <0x01>;
					mhi,num-elements = <0x20>;
					mhi,priority = <0x01>;
				};

				mhi_event@1 {
					mhi,msi = <0x02>;
					mhi,brstmode = <0x02>;
					mhi,intmod = <0x01>;
					mhi,num-elements = <0x100>;
					mhi,priority = <0x01>;
				};
			};

			mhi_channels {

				mhi_chan@0 {
					mhi,data-type = <0x00>;
					mhi,chan-dir = <0x01>;
					mhi,num-elements = <0x20>;
					reg = <0x00>;
					mhi,ee = <0x14>;
					label = "LOOPBACK";
					mhi,doorbell-mode = <0x02>;
					mhi,event-ring = <0x01>;
				};

				mhi_chan@4 {
					mhi,data-type = <0x00>;
					mhi,chan-dir = <0x01>;
					mhi,num-elements = <0x20>;
					reg = <0x04>;
					mhi,ee = <0x14>;
					label = "DIAG";
					mhi,doorbell-mode = <0x02>;
					mhi,event-ring = <0x01>;
				};

				mhi_chan@5 {
					mhi,data-type = <0x00>;
					mhi,chan-dir = <0x02>;
					mhi,num-elements = <0x20>;
					reg = <0x05>;
					mhi,ee = <0x14>;
					label = "DIAG";
					mhi,doorbell-mode = <0x02>;
					mhi,event-ring = <0x01>;
				};

				mhi_chan@1 {
					mhi,data-type = <0x00>;
					mhi,chan-dir = <0x02>;
					mhi,num-elements = <0x20>;
					reg = <0x01>;
					mhi,ee = <0x14>;
					label = "LOOPBACK";
					mhi,doorbell-mode = <0x02>;
					mhi,event-ring = <0x01>;
				};

				mhi_chan@21 {
					mhi,data-type = <0x00>;
					mhi,chan-dir = <0x02>;
					mhi,num-elements = <0x20>;
					reg = <0x15>;
					mhi,ee = <0x14>;
					label = "IPCR";
					mhi,auto-start;
					mhi,doorbell-mode = <0x02>;
					mhi,event-ring = <0x01>;
					mhi,auto-queue;
				};

				mhi_chan@20 {
					mhi,data-type = <0x01>;
					mhi,chan-dir = <0x01>;
					mhi,num-elements = <0x20>;
					reg = <0x14>;
					mhi,ee = <0x14>;
					label = "IPCR";
					mhi,auto-start;
					mhi,doorbell-mode = <0x02>;
					mhi,event-ring = <0x01>;
				};
			};
		};

		cti@6199000 {
			cpu = <0x3f>;
			reg = <0x6199000 0x1000>;
			clocks = <0x03 0xbf 0x03 0xbe>;
			compatible = "arm,coresight-cti";
			coresight-name = "coresight-cti-cpu1";
			reg-names = "cti-base";
			clock-names = "core_clk\0core_a_clk";
		};

		ess-switch@3a000000 {
			bm_tick_mode = <0x00>;
			tm_tick_mode = <0x00>;
			switch_inner_bmp = <0xc0>;
			reg = <0x3a000000 0x1000000>;
			switch_cpu_bmp = <0x01>;
			clocks = <0x03 0xb7 0x03 0xb8 0x03 0x8d 0x03 0x98 0x03 0x99 0x03 0x9c 0x03 0x7b 0x03 0x7c 0x03 0x7d 0x03 0x7e 0x03 0x7f 0x03 0x70 0x03 0x6f 0x03 0x77 0x03 0x76 0x03 0x63 0x03 0x62 0x03 0x71 0x03 0x5b 0x03 0x64 0x03 0xae 0x03 0x60 0x03 0x72 0x03 0x65 0x03 0x66 0x03 0x67 0x03 0x68 0x03 0x69 0x03 0x6a 0x03 0x6b 0x03 0x6c 0x03 0x6d 0x03 0x6e 0x03 0x8e 0x03 0x8f 0x03 0x90 0x03 0x91 0x03 0x92 0x03 0x93 0x03 0x94 0x03 0x95 0x03 0x96 0x03 0x97 0x03 0x9a 0x03 0x9b 0x03 0x0c 0x03 0x0d 0x03 0xf2>;
			reset-names = "ppe_rst\0uniphy0_soft_rst\0uniphy0_xpcs_rst\0uniphy1_soft_rst\0uniphy1_xpcs_rst\0nss_port1_rst\0nss_port2_rst\0nss_port3_rst\0nss_port4_rst\0nss_port5_rst\0uniphy0_port1_dis\0uniphy0_port2_dis\0uniphy0_port3_dis\0uniphy0_port4_dis\0uniphy0_port5_dis\0uniphy0_port_4_5_rst\0uniphy0_port_4_rst";
			compatible = "qcom,ess-switch-ipq60xx";
			switch_mac_mode = <0x00>;
			switch_lan_bmp = <0x1e>;
			switch_wan_bmp = <0x20>;
			switch_access_mode = "local bus";
			resets = <0x03 0x68 0x03 0x69 0x03 0x6a 0x03 0x6b 0x03 0x6c 0x03 0x70 0x03 0x71 0x03 0x72 0x03 0x73 0x03 0x74 0x03 0x75 0x03 0x76 0x03 0x77 0x03 0x78 0x03 0x79 0x03 0x7a 0x03 0x7b>;
			clock-names = "cmn_ahb_clk\0cmn_sys_clk\0uniphy0_ahb_clk\0uniphy0_sys_clk\0uniphy1_ahb_clk\0uniphy1_sys_clk\0port1_mac_clk\0port2_mac_clk\0port3_mac_clk\0port4_mac_clk\0port5_mac_clk\0nss_ppe_clk\0nss_ppe_cfg_clk\0nssnoc_ppe_clk\0nssnoc_ppe_cfg_clk\0nss_edma_clk\0nss_edma_cfg_clk\0nss_ppe_ipe_clk\0gcc_mdio_ahb_clk\0gcc_nss_noc_clk\0gcc_nssnoc_snoc_clk\0gcc_nss_crypto_clk\0gcc_nss_ptp_ref_clk\0nss_port1_rx_clk\0nss_port1_tx_clk\0nss_port2_rx_clk\0nss_port2_tx_clk\0nss_port3_rx_clk\0nss_port3_tx_clk\0nss_port4_rx_clk\0nss_port4_tx_clk\0nss_port5_rx_clk\0nss_port5_tx_clk\0uniphy0_port1_rx_clk\0uniphy0_port1_tx_clk\0uniphy0_port2_rx_clk\0uniphy0_port2_tx_clk\0uniphy0_port3_rx_clk\0uniphy0_port3_tx_clk\0uniphy0_port4_rx_clk\0uniphy0_port4_tx_clk\0uniphy0_port5_rx_clk\0uniphy0_port5_tx_clk\0uniphy1_port5_rx_clk\0uniphy1_port5_tx_clk\0nss_port5_rx_clk_src\0nss_port5_tx_clk_src\0gcc_snoc_nssnoc_clk";
			switch_mac_mode1 = <0xff>;
			switch_mac_mode2 = <0xff>;

			qcom,port_phyinfo {

				port@2 {
					port_id = <0x03>;
					phy_address = <0x02>;
				};

				port@0 {
					port_id = <0x01>;
					phy_address = <0x00>;
				};

				port@1 {
					port_id = <0x02>;
					phy_address = <0x01>;
				};

				port@4 {
					port_id = <0x05>;
					phy_address = <0x04>;
				};

				port@3 {
					port_id = <0x04>;
					phy_address = <0x03>;
				};
			};

			port_scheduler_config {

				port@2 {
					port_id = <0x02>;

					l0scheduler {

						group@0 {
							ucast_queue = <0xa0>;
							mcast_loop_pri = <0x04>;
							mcast_queue = <0x114>;
							cfg = <0x28 0x00 0x40 0x00 0x40>;
							ucast_loop_pri = <0x10>;
						};
					};

					l1scheduler {

						group@0 {
							sp = <0x28>;
							cfg = <0x00 0x0c 0x00 0x0c>;
						};

						group@1 {
							sp = <0x29>;
							cfg = <0x01 0x0d 0x01 0x0d>;
						};
					};
				};

				port@7 {
					port_id = <0x07>;

					l0scheduler {

						group@0 {
							ucast_queue = <0xf0>;
							mcast_queue = <0x128>;
							cfg = <0x3c 0x00 0x90 0x00 0x90>;
							ucast_loop_pri = <0x10>;
						};
					};

					l1scheduler {

						group@0 {
							sp = <0x3c>;
							cfg = <0x00 0x20 0x00 0x20>;
						};

						group@1 {
							sp = <0x3d>;
							cfg = <0x01 0x21 0x01 0x21>;
						};
					};
				};

				port@0 {
					port_id = <0x00>;

					l0scheduler {

						group@2 {
							ucast_queue = <0x02 0x06 0x0a>;
							mcast_queue = <0x102 0x106>;
							cfg = <0x00 0x02 0x02 0x02 0x02>;
						};

						group@0 {
							ucast_queue = <0x00 0x04 0x08>;
							mcast_queue = <0x100 0x104>;
							cfg = <0x00 0x00 0x00 0x00 0x00>;
						};

						group@3 {
							ucast_queue = <0x03 0x07 0x0b>;
							mcast_queue = <0x103 0x107>;
							cfg = <0x00 0x03 0x03 0x03 0x03>;
						};

						group@1 {
							ucast_queue = <0x01 0x05 0x09>;
							mcast_queue = <0x101 0x105>;
							cfg = <0x00 0x01 0x01 0x01 0x01>;
						};
					};

					l1scheduler {

						group@0 {
							sp = <0x00 0x01>;
							cfg = <0x00 0x00 0x00 0x00>;
						};
					};
				};

				port@1 {
					port_id = <0x01>;

					l0scheduler {

						group@0 {
							ucast_queue = <0x90>;
							mcast_loop_pri = <0x04>;
							mcast_queue = <0x110>;
							cfg = <0x24 0x00 0x30 0x00 0x30>;
							ucast_loop_pri = <0x10>;
						};
					};

					l1scheduler {

						group@0 {
							sp = <0x24>;
							cfg = <0x00 0x08 0x00 0x08>;
						};

						group@1 {
							sp = <0x25>;
							cfg = <0x01 0x09 0x01 0x09>;
						};
					};
				};

				port@6 {
					port_id = <0x06>;

					l0scheduler {

						group@0 {
							ucast_queue = <0xe0>;
							mcast_loop_pri = <0x04>;
							mcast_queue = <0x124>;
							cfg = <0x38 0x00 0x80 0x00 0x80>;
							ucast_loop_pri = <0x10>;
						};
					};

					l1scheduler {

						group@0 {
							sp = <0x38>;
							cfg = <0x00 0x1c 0x00 0x1c>;
						};

						group@1 {
							sp = <0x39>;
							cfg = <0x01 0x1d 0x01 0x1d>;
						};
					};
				};

				port@4 {
					port_id = <0x04>;

					l0scheduler {

						group@0 {
							ucast_queue = <0xc0>;
							mcast_loop_pri = <0x04>;
							mcast_queue = <0x11c>;
							cfg = <0x30 0x00 0x60 0x00 0x60>;
							ucast_loop_pri = <0x10>;
						};
					};

					l1scheduler {

						group@0 {
							sp = <0x30>;
							cfg = <0x00 0x14 0x00 0x14>;
						};

						group@1 {
							sp = <0x31>;
							cfg = <0x01 0x15 0x01 0x15>;
						};
					};
				};

				port@3 {
					port_id = <0x03>;

					l0scheduler {

						group@0 {
							ucast_queue = <0xb0>;
							mcast_loop_pri = <0x04>;
							mcast_queue = <0x118>;
							cfg = <0x2c 0x00 0x50 0x00 0x50>;
							ucast_loop_pri = <0x10>;
						};
					};

					l1scheduler {

						group@0 {
							sp = <0x2c>;
							cfg = <0x00 0x10 0x00 0x10>;
						};

						group@1 {
							sp = <0x2d>;
							cfg = <0x01 0x11 0x01 0x11>;
						};
					};
				};

				port@5 {
					port_id = <0x05>;

					l0scheduler {

						group@0 {
							ucast_queue = <0xd0>;
							mcast_loop_pri = <0x04>;
							mcast_queue = <0x120>;
							cfg = <0x34 0x00 0x70 0x00 0x70>;
							ucast_loop_pri = <0x10>;
						};
					};

					l1scheduler {

						group@0 {
							sp = <0x34>;
							cfg = <0x00 0x18 0x00 0x18>;
						};

						group@1 {
							sp = <0x35>;
							cfg = <0x01 0x19 0x01 0x19>;
						};
					};
				};
			};

			port_scheduler_resource {

				port@2 {
					l0cdrr = <0x40 0x4f>;
					l1cdrr = <0x0c 0x0f>;
					ucast_queue = <0xa0 0xaf>;
					l0edrr = <0x40 0x4f>;
					l1edrr = <0x0c 0x0f>;
					port_id = <0x02>;
					mcast_queue = <0x114 0x117>;
					l0sp = <0x28 0x2b>;
				};

				port@7 {
					l0cdrr = <0x90 0x9f>;
					l1cdrr = <0x20 0x23>;
					ucast_queue = <0xf0 0xff>;
					l0edrr = <0x90 0x9f>;
					l1edrr = <0x20 0x23>;
					port_id = <0x07>;
					mcast_queue = <0x128 0x12b>;
					l0sp = <0x3c 0x3f>;
				};

				port@0 {
					l0cdrr = <0x00 0x2f>;
					l1cdrr = <0x00 0x07>;
					ucast_queue = <0x00 0x8f>;
					l0edrr = <0x00 0x2f>;
					l1edrr = <0x00 0x07>;
					port_id = <0x00>;
					mcast_queue = <0x100 0x10f>;
					l0sp = <0x00 0x23>;
				};

				port@1 {
					l0cdrr = <0x30 0x3f>;
					l1cdrr = <0x08 0x0b>;
					ucast_queue = <0x90 0x9f>;
					l0edrr = <0x30 0x3f>;
					l1edrr = <0x08 0x0b>;
					port_id = <0x01>;
					mcast_queue = <0x110 0x113>;
					l0sp = <0x24 0x27>;
				};

				port@6 {
					l0cdrr = <0x80 0x8f>;
					l1cdrr = <0x1c 0x1f>;
					ucast_queue = <0xe0 0xef>;
					l0edrr = <0x80 0x8f>;
					l1edrr = <0x1c 0x1f>;
					port_id = <0x06>;
					mcast_queue = <0x124 0x127>;
					l0sp = <0x38 0x3b>;
				};

				port@4 {
					l0cdrr = <0x60 0x6f>;
					l1cdrr = <0x14 0x17>;
					ucast_queue = <0xc0 0xcf>;
					l0edrr = <0x60 0x6f>;
					l1edrr = <0x14 0x17>;
					port_id = <0x04>;
					mcast_queue = <0x11c 0x11f>;
					l0sp = <0x30 0x33>;
				};

				port@3 {
					l0cdrr = <0x50 0x5f>;
					l1cdrr = <0x10 0x13>;
					ucast_queue = <0xb0 0xbf>;
					l0edrr = <0x50 0x5f>;
					l1edrr = <0x10 0x13>;
					port_id = <0x03>;
					mcast_queue = <0x118 0x11b>;
					l0sp = <0x2c 0x2f>;
				};

				port@5 {
					l0cdrr = <0x70 0x7f>;
					l1cdrr = <0x18 0x1b>;
					ucast_queue = <0xd0 0xdf>;
					l0edrr = <0x70 0x7f>;
					l1edrr = <0x18 0x1b>;
					port_id = <0x05>;
					mcast_queue = <0x120 0x123>;
					l0sp = <0x34 0x37>;
				};
			};
		};

		cti@6017000 {
			reg = <0x6017000 0x1000>;
			clocks = <0x03 0xbf 0x03 0xbe>;
			compatible = "arm,coresight-cti";
			coresight-name = "coresight-cti7";
			reg-names = "cti-base";
			clock-names = "core_clk\0core_a_clk";
		};

		cti@619b000 {
			cpu = <0x43>;
			reg = <0x619b000 0x1000>;
			clocks = <0x03 0xbf 0x03 0xbe>;
			compatible = "arm,coresight-cti";
			coresight-name = "coresight-cti-cpu3";
			reg-names = "cti-base";
			clock-names = "core_clk\0core_a_clk";
		};

		cti@6015000 {
			reg = <0x6015000 0x1000>;
			clocks = <0x03 0xbf 0x03 0xbe>;
			compatible = "arm,coresight-cti";
			coresight-name = "coresight-cti5";
			reg-names = "cti-base";
			clock-names = "core_clk\0core_a_clk";
		};

		cti@6010000 {
			linux,phandle = <0x25>;
			reg = <0x6010000 0x1000>;
			phandle = <0x25>;
			clocks = <0x03 0xbf 0x03 0xbe>;
			compatible = "arm,coresight-cti";
			coresight-name = "coresight-cti0";
			reg-names = "cti-base";
			clock-names = "core_clk\0core_a_clk";
		};

		i2c@78b7000 {
			pinctrl-0 = <0x0e>;
			dma-names = "rx\0tx";
			#size-cells = <0x00>;
			dmas = <0x0d 0x11 0x0d 0x10>;
			reg = <0x78b7000 0x600>;
			pinctrl-names = "default";
			clocks = <0x03 0x43 0x03 0x48>;
			compatible = "qcom,i2c-qup-v2.2.1";
			#address-cells = <0x01>;
			clock-frequency = <0x61a80>;
			interrupts = <0x00 0x61 0x04>;
			clock-names = "iface\0core";
			status = "ok";
		};

		qcom,sps {
			qcom,pipe-attr-ee;
			compatible = "qcom,msm_sps_4k";
		};

		dbgui@6108000 {
			qcom,dbgui-addr-offset = <0x30>;
			reg = <0x6108000 0x1000>;
			qcom,dbgui-size = <0x40>;
			clocks = <0x03 0xbf 0x03 0xbe>;
			compatible = "qcom,coresight-dbgui";
			qcom,dbgui-data-offset = <0x130>;
			coresight-name = "coresight-dbgui";
			reg-names = "dbgui-base";
			clock-names = "core_clk\0core_a_clk";

			port {

				endpoint {
					linux,phandle = <0x34>;
					phandle = <0x34>;
					remote-endpoint = <0x47>;
				};
			};
		};

		syscon@b111000 {
			linux,phandle = <0x10>;
			reg = <0xb111000 0x1000>;
			phandle = <0x10>;
			compatible = "syscon";
		};

		qcom,gadget_diag@0 {
			compatible = "qcom,gadget-diag";
			status = "disabled";
		};

		serial@78b0000 {
			reg = <0x78b0000 0x200>;
			clocks = <0x03 0x51 0x03 0x43>;
			compatible = "qcom,msm-uartdm-v1.4\0qcom,msm-uartdm";
			interrupts = <0x00 0x6c 0x04>;
			clock-names = "core\0iface";
			status = "disabled";
		};

		i2c@78b6000 {
			dma-names = "rx\0tx";
			#size-cells = <0x00>;
			dmas = <0x0d 0x0f 0x0d 0x0e>;
			reg = <0x78b6000 0x600>;
			clocks = <0x03 0x43 0x03 0x46>;
			compatible = "qcom,i2c-qup-v2.2.1";
			#address-cells = <0x01>;
			clock-frequency = <0x61a80>;
			interrupts = <0x00 0x60 0x04>;
			clock-names = "iface\0core";
			status = "disabled";
		};

		nss-common {
			reg = <0x1868010 0x1000 0x40000000 0x1000>;
			compatible = "qcom,nss-common";
			reg-names = "nss-misc-reset\0nss-misc-reset-flag";
		};

		mailboxrpm@b111000 {
			linux,phandle = <0x14>;
			qcom,ipc = <0x10 0x08 0x00>;
			phandle = <0x14>;
			compatible = "qcom,msm8996-apcs-hmss-global";
			#mbox-cells = <0x01>;
		};

		mailboxlpass@b111000 {
			linux,phandle = <0x23>;
			qcom,ipc = <0x10 0x08 0x17>;
			phandle = <0x23>;
			compatible = "qcom,msm8996-apcs-hmss-global";
			#mbox-cells = <0x01>;
		};

		mdio@90000 {
			pinctrl-0 = <0x20>;
			phy-reset-gpio = <0x0c 0x4b 0x00>;
			#size-cells = <0x01>;
			reg = <0x90000 0x64>;
			pinctrl-names = "default";
			compatible = "qcom,qca-mdio\0qcom,ipq40xx-mdio";
			#address-cells = <0x01>;
			status = "ok";

			ethernet-phy@3 {
				reg = <0x02>;
			};

			ethernet-phy@0 {
				reg = <0x01>;
			};

			ethernet-phy@1 {
				reg = <0x00>;
			};

			ethernet-phy@4 {
				reg = <0x04>;
			};

			ethernet-phy@2 {
				reg = <0x03>;
			};
		};

		serial@78b3000 {
			reg = <0x78b3000 0x200>;
			clocks = <0x03 0x54 0x03 0x43>;
			compatible = "qcom,msm-uartdm-v1.4\0qcom,msm-uartdm";
			interrupts = <0x00 0x134 0x04>;
			clock-names = "core\0iface";
			status = "disabled";
		};

		qca,scm_restart_reason {
			reg = <0x193d000 0x14>;
			compatible = "qca_ipq6018,scm_restart_reason";
		};

		qusb@59000 {
			linux,phandle = <0x0a>;
			phy_type = "utmi";
			reg = <0x59000 0x180 0x70f8800 0x400 0x1841030 0x04 0x700c12c 0x04>;
			phandle = <0x0a>;
			reset-names = "usb2_phy_reset";
			compatible = "qcom,qusb2phy";
			qcom,qusb-phy-init-seq = <0x14 0x00 0xf8 0x80 0xb3 0x84 0x83 0x88 0xc0 0x8c 0x30 0x08 0x79 0x0c 0x21 0x10 0x00 0x90 0x00 0x18 0x14 0x9c 0x80 0x04 0x9f 0x1c>;
			reg-names = "qusb_phy_base\0qscratch_base\0ref_clk_addr\0usb3_guctl_addr";
			resets = <0x03 0x2c>;
			status = "ok";
		};

		ssphy@78000 {
			linux,phandle = <0x09>;
			qcom,qmp-phy-reg-offset = <0x988 0x98c 0x990 0x994 0x974 0x8d8 0x8dc 0x804 0x800 0x808>;
			qcom,qmp-phy-init-seq = <0xac 0x14 0x1a 0x00 0x34 0x08 0x08 0x00 0x174 0x30 0x30 0x00 0x3c 0x06 0x06 0x00 0xb4 0x00 0x00 0x00 0xb8 0x08 0x08 0x00 0x194 0x06 0x06 0x3e8 0x19c 0x01 0x01 0x00 0x178 0x00 0x00 0x00 0xd0 0x68 0x68 0x00 0xdc 0xab 0xab 0x00 0xe0 0xaa 0xaa 0x00 0xe4 0x02 0x02 0x00 0x78 0x09 0x09 0x00 0x84 0x16 0x16 0x00 0x90 0x28 0x28 0x00 0x108 0xa0 0xa0 0x00 0x10c 0x00 0x00 0x00 0x184 0x0a 0x0a 0x00 0x4c 0xaa 0xaa 0x00 0x50 0x29 0x29 0x00 0x54 0x00 0x00 0x00 0xc8 0x00 0x00 0x00 0x18c 0x00 0x00 0x00 0xcc 0x00 0x00 0x00 0x128 0x00 0x00 0x00 0x0c 0x0a 0x0a 0x00 0x10 0x01 0x01 0x00 0x1c 0x7d 0x7d 0x00 0x20 0x01 0x01 0x00 0x14 0x00 0x00 0x00 0x18 0x00 0x00 0x00 0x24 0x0a 0x0a 0x00 0x28 0x05 0x05 0x00 0x48 0x0f 0x0f 0x00 0x70 0x0f 0x0f 0x00 0x100 0x80 0x80 0x00 0x440 0x0b 0x0b 0x00 0x4d8 0x02 0x02 0x00 0x4dc 0x6c 0x6c 0x00 0x4e0 0xbb 0xb8 0x00 0x508 0x77 0x77 0x00 0x50c 0x80 0x80 0x00 0x514 0x03 0x03 0x00 0x51c 0x16 0x16 0x00 0x448 0x75 0x75 0x00 0x454 0x00 0x00 0x00 0x40c 0x0a 0x0a 0x00 0x41c 0x06 0x06 0x00 0x510 0x00 0x00 0x00 0x268 0x45 0x45 0x00 0x2ac 0x12 0x12 0x00 0x294 0x06 0x06 0x00 0x254 0x00 0x00 0x00 0x8c8 0x83 0x83 0x00 0x8c4 0x02 0x02 0x00 0x8cc 0x09 0x09 0x00 0x8d0 0xa2 0xa2 0x00 0x8d4 0x85 0x85 0x00 0x880 0xd1 0xd1 0x00 0x884 0x1f 0x1f 0x00 0x888 0x47 0x47 0x00 0x80c 0x9f 0x9f 0x00 0x824 0x17 0x17 0x00 0x828 0x0f 0x0f 0x00 0x8b8 0x75 0x75 0x00 0x8bc 0x13 0x13 0x00 0x8b0 0x86 0x86 0x00 0x8a0 0x04 0x04 0x00 0x88c 0x44 0x44 0x00 0x870 0xe7 0xe7 0x00 0x874 0x03 0x03 0x00 0x878 0x40 0x40 0x00 0x87c 0x00 0x00 0x00 0x9d8 0x88 0x88 0x00 0xffffffff 0xffffffff 0x00 0x00>;
			reg = <0x78000 0x45c 0x193f244 0x04 0x8af8800 0x100 0x7e000 0x18>;
			phandle = <0x09>;
			clocks = <0x03 0x9d 0x03 0xa1>;
			reset-names = "usb3_phy_reset\0usb3phy_phy_reset";
			compatible = "qcom,usb-ssphy-qmp";
			reg-names = "qmp_phy_base\0vls_clamp_reg\0qscratch_base\0ahb2phy_base";
			resets = <0x03 0x27 0x03 0x28>;
			clock-names = "aux_clk\0pipe_clk";
			status = "ok";
		};

		funnel@61a1000 {
			arm,primecell-periphid = <0x3b908>;
			reg = <0x61a1000 0x1000>;
			clocks = <0x03 0xbf 0x03 0xbe>;
			compatible = "arm,primecell";
			coresight-name = "coresight-funnel-apss0";
			reg-names = "funnel-base";
			clock-names = "apb_pclk\0core_a_clk";

			ports {
				#size-cells = <0x00>;
				#address-cells = <0x01>;

				port@2 {
					reg = <0x01>;

					endpoint {
						linux,phandle = <0x40>;
						slave-mode;
						phandle = <0x40>;
						remote-endpoint = <0x3a>;
					};
				};

				port@0 {
					reg = <0x00>;

					endpoint {
						linux,phandle = <0x37>;
						phandle = <0x37>;
						remote-endpoint = <0x38>;
					};
				};

				port@1 {
					reg = <0x00>;

					endpoint {
						linux,phandle = <0x3e>;
						slave-mode;
						phandle = <0x3e>;
						remote-endpoint = <0x39>;
					};
				};

				port@4 {
					reg = <0x03>;

					endpoint {
						linux,phandle = <0x44>;
						slave-mode;
						phandle = <0x44>;
						remote-endpoint = <0x3c>;
					};
				};

				port@3 {
					reg = <0x02>;

					endpoint {
						linux,phandle = <0x42>;
						slave-mode;
						phandle = <0x42>;
						remote-endpoint = <0x3b>;
					};
				};
			};
		};

		etm@619e000 {
			arm,primecell-periphid = <0x3b95d>;
			cpu = <0x41>;
			reg = <0x619e000 0x1000>;
			clocks = <0x03 0xbf 0x03 0xbe>;
			compatible = "arm,primecell";
			coresight-name = "coresight-etm2";
			clock-names = "apb_pclk\0core_a_clk";

			port {

				endpoint {
					linux,phandle = <0x3b>;
					phandle = <0x3b>;
					remote-endpoint = <0x42>;
				};
			};
		};

		dbm@0x8AF8000 {
			linux,phandle = <0x07>;
			qcom,reset-ep-after-lpm-resume;
			reg = <0x8af8000 0x300>;
			phandle = <0x07>;
			compatible = "qcom,usb-dbm-1p5";
		};

		cti@601e000 {
			reg = <0x601e000 0x1000>;
			clocks = <0x03 0xbf 0x03 0xbe>;
			compatible = "arm,coresight-cti";
			coresight-name = "coresight-cti14";
			reg-names = "cti-base";
			clock-names = "core_clk\0core_a_clk";
		};
	};

	psci {
		method = "smc";
		compatible = "arm,psci-1.0";
		status = "ok";
	};

	cpus {
		#size-cells = <0x00>;
		#address-cells = <0x01>;

		cpu@2 {
			linux,phandle = <0x41>;
			device_type = "cpu";
			clock-latency = <0x30d40>;
			reg = <0x02>;
			phandle = <0x41>;
			clocks = <0x4f 0x03>;
			next-level-cache = <0x4e>;
			qcom,acc = <0x51>;
			compatible = "arm,cortex-a53\0arm,armv8";
			enable-method = "psci";
			operating-points = <0xd2f00 0x10c8e0 0x101d00 0x10c8e0 0x142440 0x10c8e0 0x15f900 0x10c8e0 0x188940 0x10c8e0 0x1b7740 0x10c8e0>;
			clock-names = "cpu";
		};

		cpu@1 {
			linux,phandle = <0x3f>;
			device_type = "cpu";
			clock-latency = <0x30d40>;
			reg = <0x01>;
			phandle = <0x3f>;
			clocks = <0x4f 0x03>;
			next-level-cache = <0x4e>;
			qcom,acc = <0x50>;
			compatible = "arm,cortex-a53\0arm,armv8";
			enable-method = "psci";
			operating-points = <0xd2f00 0x10c8e0 0x101d00 0x10c8e0 0x142440 0x10c8e0 0x15f900 0x10c8e0 0x188940 0x10c8e0 0x1b7740 0x10c8e0>;
			clock-names = "cpu";
		};

		cpu@0 {
			linux,phandle = <0x3d>;
			device_type = "cpu";
			clock-latency = <0x30d40>;
			reg = <0x00>;
			phandle = <0x3d>;
			clocks = <0x4f 0x03>;
			next-level-cache = <0x4e>;
			qcom,acc = <0x4d>;
			compatible = "arm,cortex-a53\0arm,armv8";
			enable-method = "psci";
			operating-points = <0xd2f00 0x10c8e0 0x101d00 0x10c8e0 0x142440 0x10c8e0 0x15f900 0x10c8e0 0x188940 0x10c8e0 0x1b7740 0x10c8e0>;
			clock-names = "cpu";

			l2-cache {
				linux,phandle = <0x4e>;
				cache-level = <0x02>;
				phandle = <0x4e>;
				compatible = "cache";
			};
		};

		cpu@3 {
			linux,phandle = <0x43>;
			device_type = "cpu";
			clock-latency = <0x30d40>;
			reg = <0x03>;
			phandle = <0x43>;
			clocks = <0x4f 0x03>;
			next-level-cache = <0x4e>;
			qcom,acc = <0x52>;
			compatible = "arm,cortex-a53\0arm,armv8";
			enable-method = "psci";
			operating-points = <0xd2f00 0x10c8e0 0x101d00 0x10c8e0 0x142440 0x10c8e0 0x15f900 0x10c8e0 0x188940 0x10c8e0 0x1b7740 0x10c8e0>;
			clock-names = "cpu";
		};
	};

	memory {
		device_type = "memory";
		reg = <0x00 0x40000000 0x00 0x40000000>;
	};

	clocks {

		sleep_clk {
			linux,phandle = <0x1f>;
			#clock-cells = <0x00>;
			phandle = <0x1f>;
			compatible = "fixed-clock";
			clock-frequency = <0x7d00>;
		};

		usb3phy_0_cc_pipe_clk {
			#clock-cells = <0x00>;
			compatible = "fixed-clock";
			clock-frequency = <0x7735940>;
		};

		bias_pll_cc_clk {
			#clock-cells = <0x00>;
			compatible = "fixed-clock";
			clock-frequency = <0x11e1a300>;
		};

		xo {
			#clock-cells = <0x00>;
			compatible = "fixed-clock";
			clock-frequency = <0x16e3600>;
		};

		bias_pll_nss_noc_clk {
			#clock-cells = <0x00>;
			compatible = "fixed-clock";
			clock-frequency = <0x18d34920>;
		};
	};

	firmware {

		scm {
			compatible = "qcom,scm-ipq6018";
			smmu-state-scm-cmd-id = <0x20>;
		};

		qfprom_sec {
			img-size = <0x500000>;
			scm-cmd-id = <0x1f>;
			compatible = "qcom,qfprom-sec";
			img-addr = <0x4a100000>;
		};
	};

	aliases {
		sdhc1 = "/soc/sdhci@7804000";
		ethernet2 = "/soc/dp3";
		ethernet3 = "/soc/dp4";
		ethernet1 = "/soc/dp2";
		serial0 = "/soc/serial@78b1000";
		ethernet4 = "/soc/dp5";
		ethernet0 = "/soc/dp1";
	};

	qseecom {
		mem-start = <0x49b00000>;
		compatible = "ipq6018-qseecom";
		mem-size = <0x600000>;
		status = "ok";
	};

	pmu {
		compatible = "arm,cortex-a53-pmu";
		interrupts = <0x01 0x07 0xf04>;
	};
};
